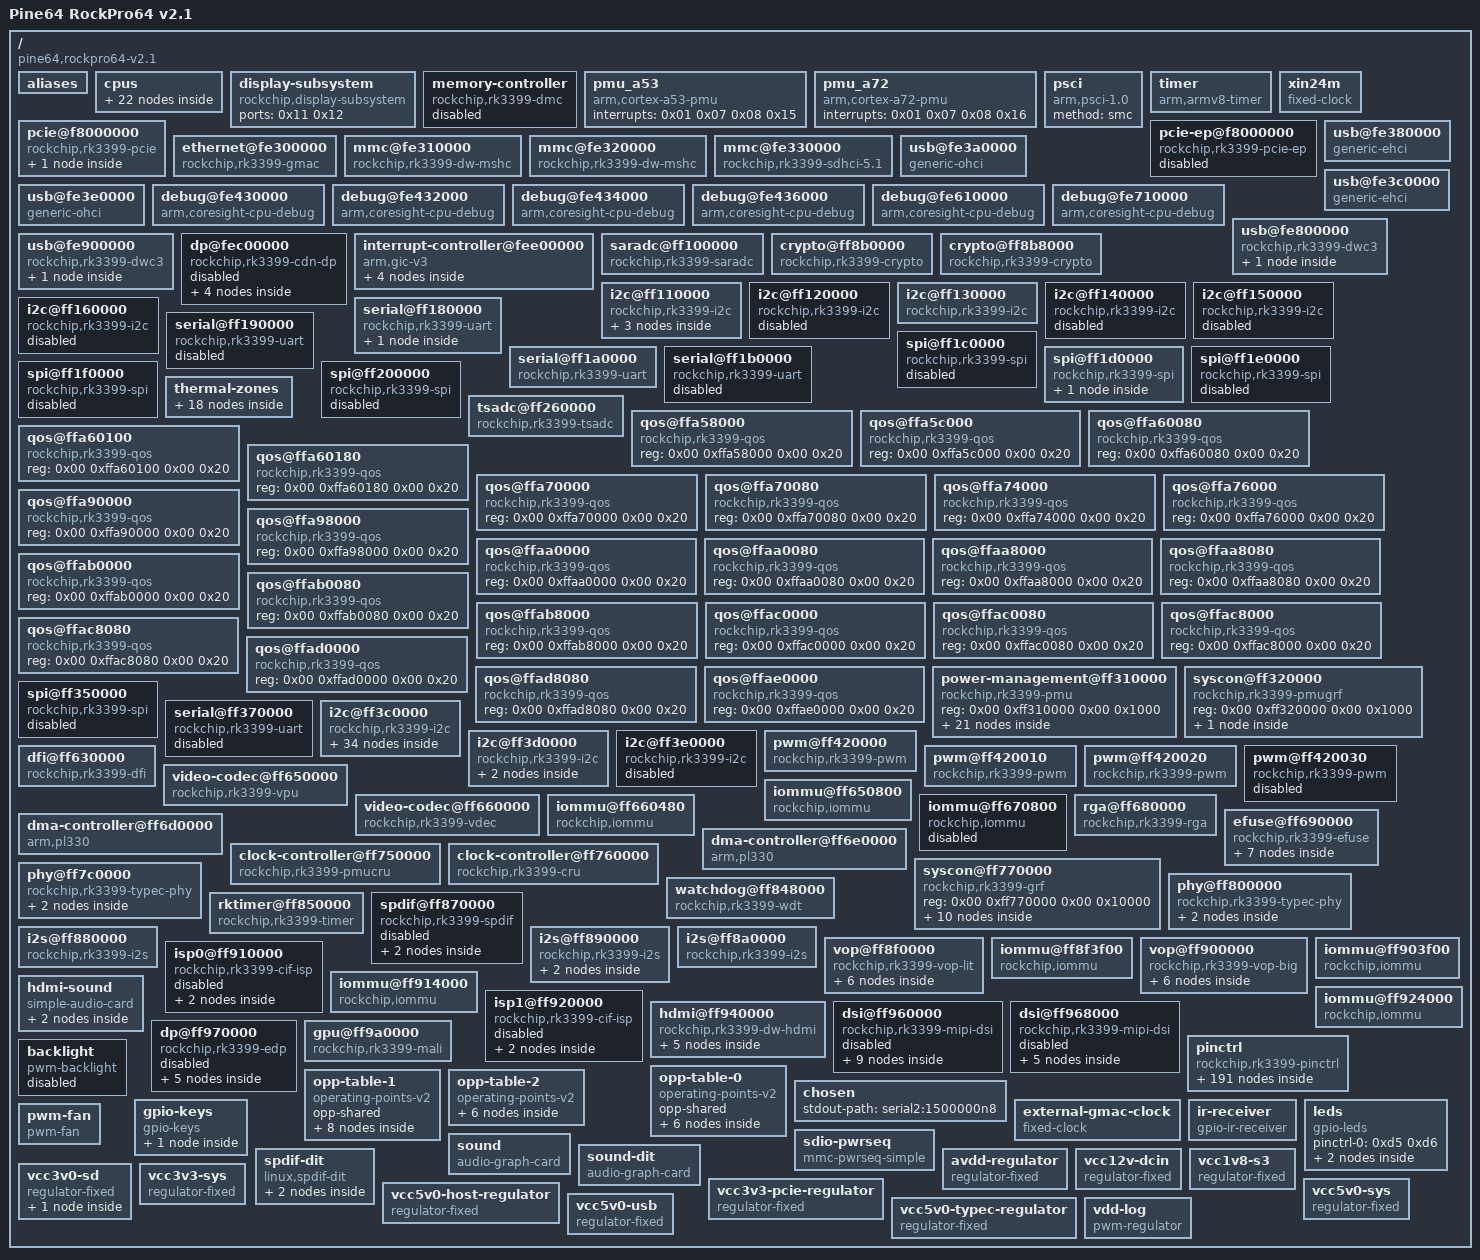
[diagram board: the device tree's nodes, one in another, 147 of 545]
/*
 * Copyright Linux Kernel Team
 *
 * SPDX-License-Identifier: GPL-2.0-only
 *
 * This file is derived from an intermediate build stage of the
 * Linux kernel. The licenses of all input files to this process
 * are compatible with GPL-2.0-only.
 */

/dts-v1/;

/ {
	compatible = "pine64,rockpro64-v2.1", "pine64,rockpro64", "rockchip,rk3399";
	interrupt-parent = <0x01>;
	#address-cells = <0x02>;
	#size-cells = <0x02>;
	model = "Pine64 RockPro64 v2.1";

	aliases {
		gpio0 = "/pinctrl/gpio@ff720000";
		gpio1 = "/pinctrl/gpio@ff730000";
		gpio2 = "/pinctrl/gpio@ff780000";
		gpio3 = "/pinctrl/gpio@ff788000";
		gpio4 = "/pinctrl/gpio@ff790000";
		i2c0 = "/i2c@ff3c0000";
		i2c1 = "/i2c@ff110000";
		i2c2 = "/i2c@ff120000";
		i2c3 = "/i2c@ff130000";
		i2c4 = "/i2c@ff3d0000";
		i2c5 = "/i2c@ff140000";
		i2c6 = "/i2c@ff150000";
		i2c7 = "/i2c@ff160000";
		i2c8 = "/i2c@ff3e0000";
		serial0 = "/serial@ff180000";
		serial1 = "/serial@ff190000";
		serial2 = "/serial@ff1a0000";
		serial3 = "/serial@ff1b0000";
		serial4 = "/serial@ff370000";
		spi0 = "/spi@ff1c0000";
		spi1 = "/spi@ff1d0000";
		spi2 = "/spi@ff1e0000";
		spi3 = "/spi@ff350000";
		spi4 = "/spi@ff1f0000";
		spi5 = "/spi@ff200000";
		ethernet0 = "/ethernet@fe300000";
		mmc0 = "/mmc@fe310000";
		mmc1 = "/mmc@fe320000";
		mmc2 = "/mmc@fe330000";
	};

	cpus {
		#address-cells = <0x02>;
		#size-cells = <0x00>;

		cpu-map {

			cluster0 {

				core0 {
					cpu = <0x02>;
				};

				core1 {
					cpu = <0x03>;
				};

				core2 {
					cpu = <0x04>;
				};

				core3 {
					cpu = <0x05>;
				};
			};

			cluster1 {

				core0 {
					cpu = <0x06>;
				};

				core1 {
					cpu = <0x07>;
				};
			};
		};

		cpu@0 {
			device_type = "cpu";
			compatible = "arm,cortex-a53";
			reg = <0x00 0x00>;
			enable-method = "psci";
			capacity-dmips-mhz = <0x1e5>;
			clocks = <0x08 0x08>;
			#cooling-cells = <0x02>;
			dynamic-power-coefficient = <0x64>;
			cpu-idle-states = <0x09 0x0a>;
			i-cache-size = <0x8000>;
			i-cache-line-size = <0x40>;
			i-cache-sets = <0x100>;
			d-cache-size = <0x8000>;
			d-cache-line-size = <0x40>;
			d-cache-sets = <0x80>;
			next-level-cache = <0x0b>;
			operating-points-v2 = <0x0c>;
			cpu-supply = <0x0d>;
			phandle = <0x02>;
		};

		cpu@1 {
			device_type = "cpu";
			compatible = "arm,cortex-a53";
			reg = <0x00 0x01>;
			enable-method = "psci";
			capacity-dmips-mhz = <0x1e5>;
			clocks = <0x08 0x08>;
			#cooling-cells = <0x02>;
			dynamic-power-coefficient = <0x64>;
			cpu-idle-states = <0x09 0x0a>;
			i-cache-size = <0x8000>;
			i-cache-line-size = <0x40>;
			i-cache-sets = <0x100>;
			d-cache-size = <0x8000>;
			d-cache-line-size = <0x40>;
			d-cache-sets = <0x80>;
			next-level-cache = <0x0b>;
			operating-points-v2 = <0x0c>;
			cpu-supply = <0x0d>;
			phandle = <0x03>;
		};

		cpu@2 {
			device_type = "cpu";
			compatible = "arm,cortex-a53";
			reg = <0x00 0x02>;
			enable-method = "psci";
			capacity-dmips-mhz = <0x1e5>;
			clocks = <0x08 0x08>;
			#cooling-cells = <0x02>;
			dynamic-power-coefficient = <0x64>;
			cpu-idle-states = <0x09 0x0a>;
			i-cache-size = <0x8000>;
			i-cache-line-size = <0x40>;
			i-cache-sets = <0x100>;
			d-cache-size = <0x8000>;
			d-cache-line-size = <0x40>;
			d-cache-sets = <0x80>;
			next-level-cache = <0x0b>;
			operating-points-v2 = <0x0c>;
			cpu-supply = <0x0d>;
			phandle = <0x04>;
		};

		cpu@3 {
			device_type = "cpu";
			compatible = "arm,cortex-a53";
			reg = <0x00 0x03>;
			enable-method = "psci";
			capacity-dmips-mhz = <0x1e5>;
			clocks = <0x08 0x08>;
			#cooling-cells = <0x02>;
			dynamic-power-coefficient = <0x64>;
			cpu-idle-states = <0x09 0x0a>;
			i-cache-size = <0x8000>;
			i-cache-line-size = <0x40>;
			i-cache-sets = <0x100>;
			d-cache-size = <0x8000>;
			d-cache-line-size = <0x40>;
			d-cache-sets = <0x80>;
			next-level-cache = <0x0b>;
			operating-points-v2 = <0x0c>;
			cpu-supply = <0x0d>;
			phandle = <0x05>;
		};

		cpu@100 {
			device_type = "cpu";
			compatible = "arm,cortex-a72";
			reg = <0x00 0x100>;
			enable-method = "psci";
			capacity-dmips-mhz = <0x400>;
			clocks = <0x08 0x09>;
			#cooling-cells = <0x02>;
			dynamic-power-coefficient = <0x1b4>;
			cpu-idle-states = <0x09 0x0a>;
			i-cache-size = <0xc000>;
			i-cache-line-size = <0x40>;
			i-cache-sets = <0x100>;
			d-cache-size = <0x8000>;
			d-cache-line-size = <0x40>;
			d-cache-sets = <0x100>;
			next-level-cache = <0x0e>;
			operating-points-v2 = <0x0f>;
			cpu-supply = <0x10>;
			phandle = <0x06>;

			thermal-idle {
				#cooling-cells = <0x02>;
				duration-us = <0x2710>;
				exit-latency-us = <0x1f4>;
			};
		};

		cpu@101 {
			device_type = "cpu";
			compatible = "arm,cortex-a72";
			reg = <0x00 0x101>;
			enable-method = "psci";
			capacity-dmips-mhz = <0x400>;
			clocks = <0x08 0x09>;
			#cooling-cells = <0x02>;
			dynamic-power-coefficient = <0x1b4>;
			cpu-idle-states = <0x09 0x0a>;
			i-cache-size = <0xc000>;
			i-cache-line-size = <0x40>;
			i-cache-sets = <0x100>;
			d-cache-size = <0x8000>;
			d-cache-line-size = <0x40>;
			d-cache-sets = <0x100>;
			next-level-cache = <0x0e>;
			operating-points-v2 = <0x0f>;
			cpu-supply = <0x10>;
			phandle = <0x07>;

			thermal-idle {
				#cooling-cells = <0x02>;
				duration-us = <0x2710>;
				exit-latency-us = <0x1f4>;
			};
		};

		l2-cache-cluster0 {
			compatible = "cache";
			cache-level = <0x02>;
			cache-unified;
			cache-size = <0x80000>;
			cache-line-size = <0x40>;
			cache-sets = <0x200>;
			phandle = <0x0b>;
		};

		l2-cache-cluster1 {
			compatible = "cache";
			cache-level = <0x02>;
			cache-unified;
			cache-size = <0x100000>;
			cache-line-size = <0x40>;
			cache-sets = <0x400>;
			phandle = <0x0e>;
		};

		idle-states {
			entry-method = "psci";

			cpu-sleep {
				compatible = "arm,idle-state";
				local-timer-stop;
				arm,psci-suspend-param = <0x10000>;
				entry-latency-us = <0x78>;
				exit-latency-us = <0xfa>;
				min-residency-us = <0x384>;
				phandle = <0x09>;
			};

			cluster-sleep {
				compatible = "arm,idle-state";
				local-timer-stop;
				arm,psci-suspend-param = <0x1010000>;
				entry-latency-us = <0x190>;
				exit-latency-us = <0x1f4>;
				min-residency-us = <0x7d0>;
				phandle = <0x0a>;
			};
		};
	};

	display-subsystem {
		compatible = "rockchip,display-subsystem";
		ports = <0x11 0x12>;
	};

	memory-controller {
		compatible = "rockchip,rk3399-dmc";
		rockchip,pmu = <0x13>;
		devfreq-events = <0x14>;
		clocks = <0x08 0xa8>;
		clock-names = "dmc_clk";
		status = "disabled";
	};

	pmu_a53 {
		compatible = "arm,cortex-a53-pmu";
		interrupts = <0x01 0x07 0x08 0x15>;
	};

	pmu_a72 {
		compatible = "arm,cortex-a72-pmu";
		interrupts = <0x01 0x07 0x08 0x16>;
	};

	psci {
		compatible = "arm,psci-1.0";
		method = "smc";
	};

	timer {
		compatible = "arm,armv8-timer";
		interrupts = <0x01 0x0d 0x08 0x00 0x01 0x0e 0x08 0x00 0x01 0x0b 0x08 0x00 0x01 0x0a 0x08 0x00>;
		arm,no-tick-in-suspend;
	};

	xin24m {
		compatible = "fixed-clock";
		clock-frequency = <0x16e3600>;
		clock-output-names = "xin24m";
		#clock-cells = <0x00>;
		phandle = <0x9f>;
	};

	pcie@f8000000 {
		compatible = "rockchip,rk3399-pcie";
		reg = <0x00 0xf8000000 0x00 0x2000000 0x00 0xfd000000 0x00 0x1000000>;
		reg-names = "axi-base", "apb-base";
		device_type = "pci";
		#address-cells = <0x03>;
		#size-cells = <0x02>;
		#interrupt-cells = <0x01>;
		aspm-no-l0s;
		bus-range = <0x00 0x1f>;
		clocks = <0x08 0xc5 0x08 0xc4 0x08 0x147 0x08 0xa0>;
		clock-names = "aclk", "aclk-perf", "hclk", "pm";
		interrupts = <0x00 0x31 0x04 0x00 0x00 0x32 0x04 0x00 0x00 0x33 0x04 0x00>;
		interrupt-names = "sys", "legacy", "client";
		interrupt-map-mask = <0x00 0x00 0x00 0x07>;
		interrupt-map = <0x00 0x00 0x00 0x01 0x17 0x00 0x00 0x00 0x00 0x02 0x17 0x01 0x00 0x00 0x00 0x03 0x17 0x02 0x00 0x00 0x00 0x04 0x17 0x03>;
		max-link-speed = <0x01>;
		msi-map = <0x00 0x18 0x00 0x1000>;
		phys = <0x19 0x00 0x19 0x01 0x19 0x02 0x19 0x03>;
		phy-names = "pcie-phy-0", "pcie-phy-1", "pcie-phy-2", "pcie-phy-3";
		ranges = <0x82000000 0x00 0xfa000000 0x00 0xfa000000 0x00 0x1e00000 0x81000000 0x00 0xfbe00000 0x00 0xfbe00000 0x00 0x100000>;
		resets = <0x08 0x82 0x08 0x83 0x08 0x84 0x08 0x85 0x08 0x86 0x08 0x81 0x08 0x80>;
		reset-names = "core", "mgmt", "mgmt-sticky", "pipe", "pm", "pclk", "aclk";
		status = "okay";
		ep-gpios = <0x1a 0x1c 0x00>;
		num-lanes = <0x04>;
		pinctrl-names = "default";
		pinctrl-0 = <0x1b>;
		vpcie12v-supply = <0x1c>;
		vpcie3v3-supply = <0x1d>;

		interrupt-controller {
			interrupt-controller;
			#address-cells = <0x00>;
			#interrupt-cells = <0x01>;
			phandle = <0x17>;
		};
	};

	pcie-ep@f8000000 {
		compatible = "rockchip,rk3399-pcie-ep";
		reg = <0x00 0xfd000000 0x00 0x1000000 0x00 0xfa000000 0x00 0x2000000>;
		reg-names = "apb-base", "mem-base";
		clocks = <0x08 0xc5 0x08 0xc4 0x08 0x147 0x08 0xa0>;
		clock-names = "aclk", "aclk-perf", "hclk", "pm";
		max-functions = [08];
		num-lanes = <0x04>;
		resets = <0x08 0x82 0x08 0x83 0x08 0x84 0x08 0x85 0x08 0x86 0x08 0x81 0x08 0x80>;
		reset-names = "core", "mgmt", "mgmt-sticky", "pipe", "pm", "pclk", "aclk";
		phys = <0x19 0x00 0x19 0x01 0x19 0x02 0x19 0x03>;
		phy-names = "pcie-phy-0", "pcie-phy-1", "pcie-phy-2", "pcie-phy-3";
		rockchip,max-outbound-regions = <0x20>;
		pinctrl-names = "default";
		pinctrl-0 = <0x1e>;
		status = "disabled";
	};

	ethernet@fe300000 {
		compatible = "rockchip,rk3399-gmac";
		reg = <0x00 0xfe300000 0x00 0x10000>;
		interrupts = <0x00 0x0c 0x04 0x00>;
		interrupt-names = "macirq";
		clocks = <0x08 0x69 0x08 0x67 0x08 0x68 0x08 0x66 0x08 0x6a 0x08 0xd5 0x08 0x166>;
		clock-names = "stmmaceth", "mac_clk_rx", "mac_clk_tx", "clk_mac_ref", "clk_mac_refout", "aclk_mac", "pclk_mac";
		power-domains = <0x1f 0x16>;
		resets = <0x08 0x89>;
		reset-names = "stmmaceth";
		rockchip,grf = <0x20>;
		snps,txpbl = <0x04>;
		status = "okay";
		assigned-clocks = <0x08 0xa6>;
		assigned-clock-parents = <0x21>;
		clock_in_out = "input";
		phy-supply = <0x22>;
		phy-mode = "rgmii";
		pinctrl-names = "default";
		pinctrl-0 = <0x23>;
		snps,reset-gpio = <0x24 0x0f 0x01>;
		snps,reset-active-low;
		snps,reset-delays-us = <0x00 0x2710 0xc350>;
		tx_delay = <0x28>;
		rx_delay = <0x11>;
	};

	mmc@fe310000 {
		compatible = "rockchip,rk3399-dw-mshc", "rockchip,rk3288-dw-mshc";
		reg = <0x00 0xfe310000 0x00 0x4000>;
		interrupts = <0x00 0x40 0x04 0x00>;
		max-frequency = <0x8f0d180>;
		clocks = <0x08 0x1ee 0x08 0x4d 0x08 0x9c 0x08 0x9d>;
		clock-names = "biu", "ciu", "ciu-drive", "ciu-sample";
		fifo-depth = <0x100>;
		power-domains = <0x1f 0x1c>;
		resets = <0x08 0x79>;
		reset-names = "reset";
		status = "okay";
		bus-width = <0x04>;
		cap-sd-highspeed;
		cap-sdio-irq;
		disable-wp;
		keep-power-in-suspend;
		mmc-pwrseq = <0x25>;
		non-removable;
		pinctrl-names = "default";
		pinctrl-0 = <0x26 0x27 0x28>;
		sd-uhs-sdr104;
	};

	mmc@fe320000 {
		compatible = "rockchip,rk3399-dw-mshc", "rockchip,rk3288-dw-mshc";
		reg = <0x00 0xfe320000 0x00 0x4000>;
		interrupts = <0x00 0x41 0x04 0x00>;
		max-frequency = <0x8f0d180>;
		assigned-clocks = <0x08 0x1cd>;
		assigned-clock-rates = <0xbebc200>;
		clocks = <0x08 0x1ce 0x08 0x4c 0x08 0x9a 0x08 0x9b>;
		clock-names = "biu", "ciu", "ciu-drive", "ciu-sample";
		fifo-depth = <0x100>;
		power-domains = <0x1f 0x1b>;
		resets = <0x08 0x7a>;
		reset-names = "reset";
		status = "okay";
		bus-width = <0x04>;
		cap-sd-highspeed;
		cd-gpios = <0x29 0x07 0x01>;
		disable-wp;
		pinctrl-names = "default";
		pinctrl-0 = <0x2a 0x2b 0x2c>;
		vmmc-supply = <0x2d>;
		vqmmc-supply = <0x2e>;
	};

	mmc@fe330000 {
		compatible = "rockchip,rk3399-sdhci-5.1", "arasan,sdhci-5.1";
		reg = <0x00 0xfe330000 0x00 0x10000>;
		interrupts = <0x00 0x0b 0x04 0x00>;
		arasan,soc-ctl-syscon = <0x20>;
		assigned-clocks = <0x08 0x4e>;
		assigned-clock-rates = <0xbebc200>;
		clocks = <0x08 0x4e 0x08 0xf0>;
		clock-names = "clk_xin", "clk_ahb";
		clock-output-names = "emmc_cardclock";
		#clock-cells = <0x00>;
		phys = <0x2f>;
		phy-names = "phy_arasan";
		power-domains = <0x1f 0x17>;
		disable-cqe-dcmd;
		status = "okay";
		bus-width = <0x08>;
		mmc-hs200-1_8v;
		non-removable;
		phandle = <0xa2>;
	};

	usb@fe380000 {
		compatible = "generic-ehci";
		reg = <0x00 0xfe380000 0x00 0x20000>;
		interrupts = <0x00 0x1a 0x04 0x00>;
		clocks = <0x08 0x1c8 0x08 0x1c9 0x30>;
		phys = <0x31>;
		phy-names = "usb";
		status = "okay";
	};

	usb@fe3a0000 {
		compatible = "generic-ohci";
		reg = <0x00 0xfe3a0000 0x00 0x20000>;
		interrupts = <0x00 0x1c 0x04 0x00>;
		clocks = <0x08 0x1c8 0x08 0x1c9 0x30>;
		phys = <0x31>;
		phy-names = "usb";
		status = "okay";
	};

	usb@fe3c0000 {
		compatible = "generic-ehci";
		reg = <0x00 0xfe3c0000 0x00 0x20000>;
		interrupts = <0x00 0x1e 0x04 0x00>;
		clocks = <0x08 0x1ca 0x08 0x1cb 0x32>;
		phys = <0x33>;
		phy-names = "usb";
		status = "okay";
	};

	usb@fe3e0000 {
		compatible = "generic-ohci";
		reg = <0x00 0xfe3e0000 0x00 0x20000>;
		interrupts = <0x00 0x20 0x04 0x00>;
		clocks = <0x08 0x1ca 0x08 0x1cb 0x32>;
		phys = <0x33>;
		phy-names = "usb";
		status = "okay";
	};

	debug@fe430000 {
		compatible = "arm,coresight-cpu-debug", "arm,primecell";
		reg = <0x00 0xfe430000 0x00 0x1000>;
		clocks = <0x08 0x14d>;
		clock-names = "apb_pclk";
		cpu = <0x02>;
	};

	debug@fe432000 {
		compatible = "arm,coresight-cpu-debug", "arm,primecell";
		reg = <0x00 0xfe432000 0x00 0x1000>;
		clocks = <0x08 0x14d>;
		clock-names = "apb_pclk";
		cpu = <0x03>;
	};

	debug@fe434000 {
		compatible = "arm,coresight-cpu-debug", "arm,primecell";
		reg = <0x00 0xfe434000 0x00 0x1000>;
		clocks = <0x08 0x14d>;
		clock-names = "apb_pclk";
		cpu = <0x04>;
	};

	debug@fe436000 {
		compatible = "arm,coresight-cpu-debug", "arm,primecell";
		reg = <0x00 0xfe436000 0x00 0x1000>;
		clocks = <0x08 0x14d>;
		clock-names = "apb_pclk";
		cpu = <0x05>;
	};

	debug@fe610000 {
		compatible = "arm,coresight-cpu-debug", "arm,primecell";
		reg = <0x00 0xfe610000 0x00 0x1000>;
		clocks = <0x08 0x14c>;
		clock-names = "apb_pclk";
		cpu = <0x06>;
	};

	debug@fe710000 {
		compatible = "arm,coresight-cpu-debug", "arm,primecell";
		reg = <0x00 0xfe710000 0x00 0x1000>;
		clocks = <0x08 0x14c>;
		clock-names = "apb_pclk";
		cpu = <0x07>;
	};

	usb@fe800000 {
		compatible = "rockchip,rk3399-dwc3";
		#address-cells = <0x02>;
		#size-cells = <0x02>;
		ranges;
		clocks = <0x08 0x81 0x08 0x83 0x08 0xf6 0x08 0xf8 0x08 0xf4 0x08 0xf9>;
		clock-names = "ref_clk", "suspend_clk", "bus_clk", "aclk_usb3_rksoc_axi_perf", "aclk_usb3", "grf_clk";
		resets = <0x08 0x125>;
		reset-names = "usb3-otg";
		status = "okay";

		usb@fe800000 {
			compatible = "snps,dwc3";
			reg = <0x00 0xfe800000 0x00 0x100000>;
			interrupts = <0x00 0x69 0x04 0x00>;
			clocks = <0x08 0x81 0x08 0xf6 0x08 0x83>;
			clock-names = "ref", "bus_early", "suspend";
			dr_mode = "host";
			phys = <0x34 0x35>;
			phy-names = "usb2-phy", "usb3-phy";
			phy_type = "utmi_wide";
			snps,dis_enblslpm_quirk;
			snps,dis-u2-freeclk-exists-quirk;
			snps,dis_u2_susphy_quirk;
			snps,dis-del-phy-power-chg-quirk;
			snps,dis-tx-ipgap-linecheck-quirk;
			power-domains = <0x1f 0x18>;
			status = "okay";
		};
	};

	usb@fe900000 {
		compatible = "rockchip,rk3399-dwc3";
		#address-cells = <0x02>;
		#size-cells = <0x02>;
		ranges;
		clocks = <0x08 0x82 0x08 0x84 0x08 0xf7 0x08 0xf8 0x08 0xf4 0x08 0xf9>;
		clock-names = "ref_clk", "suspend_clk", "bus_clk", "aclk_usb3_rksoc_axi_perf", "aclk_usb3", "grf_clk";
		resets = <0x08 0x126>;
		reset-names = "usb3-otg";
		status = "okay";

		usb@fe900000 {
			compatible = "snps,dwc3";
			reg = <0x00 0xfe900000 0x00 0x100000>;
			interrupts = <0x00 0x6e 0x04 0x00>;
			clocks = <0x08 0x82 0x08 0xf7 0x08 0x84>;
			clock-names = "ref", "bus_early", "suspend";
			dr_mode = "host";
			phys = <0x36 0x37>;
			phy-names = "usb2-phy", "usb3-phy";
			phy_type = "utmi_wide";
			snps,dis_enblslpm_quirk;
			snps,dis-u2-freeclk-exists-quirk;
			snps,dis_u2_susphy_quirk;
			snps,dis-del-phy-power-chg-quirk;
			snps,dis-tx-ipgap-linecheck-quirk;
			power-domains = <0x1f 0x18>;
			status = "okay";
		};
	};

	dp@fec00000 {
		compatible = "rockchip,rk3399-cdn-dp";
		reg = <0x00 0xfec00000 0x00 0x100000>;
		interrupts = <0x00 0x09 0x04 0x00>;
		assigned-clocks = <0x08 0x72 0x08 0xa1>;
		assigned-clock-rates = <0x5f5e100 0xbebc200>;
		clocks = <0x08 0x72 0x08 0x175 0x08 0xa1 0x08 0x16f>;
		clock-names = "core-clk", "pclk", "spdif", "grf";
		phys = <0x38 0x39>;
		power-domains = <0x1f 0x15>;
		resets = <0x08 0x103 0x08 0x148 0x08 0x14a 0x08 0xfd>;
		reset-names = "spdif", "dptx", "apb", "core";
		rockchip,grf = <0x20>;
		#sound-dai-cells = <0x01>;
		status = "disabled";

		ports {

			port {
				#address-cells = <0x01>;
				#size-cells = <0x00>;

				endpoint@0 {
					reg = <0x00>;
					remote-endpoint = <0x3a>;
					phandle = <0xb4>;
				};

				endpoint@1 {
					reg = <0x01>;
					remote-endpoint = <0x3b>;
					phandle = <0xae>;
				};
			};
		};
	};

	interrupt-controller@fee00000 {
		compatible = "arm,gic-v3";
		#interrupt-cells = <0x04>;
		#address-cells = <0x02>;
		#size-cells = <0x02>;
		ranges;
		interrupt-controller;
		reg = <0x00 0xfee00000 0x00 0x10000 0x00 0xfef00000 0x00 0xc0000 0x00 0xfff00000 0x00 0x10000 0x00 0xfff10000 0x00 0x10000 0x00 0xfff20000 0x00 0x10000>;
		interrupts = <0x01 0x09 0x04 0x00>;
		phandle = <0x01>;

		msi-controller@fee20000 {
			compatible = "arm,gic-v3-its";
			msi-controller;
			#msi-cells = <0x01>;
			reg = <0x00 0xfee20000 0x00 0x20000>;
			phandle = <0x18>;
		};

		ppi-partitions {

			interrupt-partition-0 {
				affinity = <0x02 0x03 0x04 0x05>;
				phandle = <0x15>;
			};

			interrupt-partition-1 {
				affinity = <0x06 0x07>;
				phandle = <0x16>;
			};
		};
	};

	saradc@ff100000 {
		compatible = "rockchip,rk3399-saradc";
		reg = <0x00 0xff100000 0x00 0x100>;
		interrupts = <0x00 0x3e 0x04 0x00>;
		#io-channel-cells = <0x01>;
		clocks = <0x08 0x50 0x08 0x165>;
		clock-names = "saradc", "apb_pclk";
		resets = <0x08 0xd4>;
		reset-names = "saradc-apb";
		status = "okay";
		vref-supply = <0x3c>;
	};

	crypto@ff8b0000 {
		compatible = "rockchip,rk3399-crypto";
		reg = <0x00 0xff8b0000 0x00 0x4000>;
		interrupts = <0x00 0x00 0x04 0x00>;
		clocks = <0x08 0x1d0 0x08 0x1d2 0x08 0x85>;
		clock-names = "hclk_master", "hclk_slave", "sclk";
		resets = <0x08 0xb5 0x08 0xae 0x08 0xaf>;
		reset-names = "master", "slave", "crypto-rst";
	};

	crypto@ff8b8000 {
		compatible = "rockchip,rk3399-crypto";
		reg = <0x00 0xff8b8000 0x00 0x4000>;
		interrupts = <0x00 0x87 0x04 0x00>;
		clocks = <0x08 0x1d1 0x08 0x1d3 0x08 0x86>;
		clock-names = "hclk_master", "hclk_slave", "sclk";
		resets = <0x08 0xba 0x08 0xb8 0x08 0xb9>;
		reset-names = "master", "slave", "crypto-rst";
	};

	i2c@ff110000 {
		compatible = "rockchip,rk3399-i2c";
		reg = <0x00 0xff110000 0x00 0x1000>;
		assigned-clocks = <0x08 0x41>;
		assigned-clock-rates = <0xbebc200>;
		clocks = <0x08 0x41 0x08 0x155>;
		clock-names = "i2c", "pclk";
		interrupts = <0x00 0x3b 0x04 0x00>;
		pinctrl-names = "default";
		pinctrl-0 = <0x3d>;
		#address-cells = <0x01>;
		#size-cells = <0x00>;
		status = "okay";
		i2c-scl-rising-time-ns = <0x12c>;
		i2c-scl-falling-time-ns = <0x0f>;

		codec@11 {
			compatible = "everest,es8316";
			reg = <0x11>;
			clocks = <0x08 0x59>;
			clock-names = "mclk";
			#sound-dai-cells = <0x00>;

			port {

				endpoint {
					remote-endpoint = <0x3e>;
					phandle = <0xa8>;
				};
			};
		};
	};

	i2c@ff120000 {
		compatible = "rockchip,rk3399-i2c";
		reg = <0x00 0xff120000 0x00 0x1000>;
		assigned-clocks = <0x08 0x42>;
		assigned-clock-rates = <0xbebc200>;
		clocks = <0x08 0x42 0x08 0x156>;
		clock-names = "i2c", "pclk";
		interrupts = <0x00 0x23 0x04 0x00>;
		pinctrl-names = "default";
		pinctrl-0 = <0x3f>;
		#address-cells = <0x01>;
		#size-cells = <0x00>;
		status = "disabled";
	};

	i2c@ff130000 {
		compatible = "rockchip,rk3399-i2c";
		reg = <0x00 0xff130000 0x00 0x1000>;
		assigned-clocks = <0x08 0x43>;
		assigned-clock-rates = <0xbebc200>;
		clocks = <0x08 0x43 0x08 0x157>;
		clock-names = "i2c", "pclk";
		interrupts = <0x00 0x22 0x04 0x00>;
		pinctrl-names = "default";
		pinctrl-0 = <0x40>;
		#address-cells = <0x01>;
		#size-cells = <0x00>;
		status = "okay";
		i2c-scl-rising-time-ns = <0x1c2>;
		i2c-scl-falling-time-ns = <0x0f>;
		phandle = <0xbb>;
	};

	i2c@ff140000 {
		compatible = "rockchip,rk3399-i2c";
		reg = <0x00 0xff140000 0x00 0x1000>;
		assigned-clocks = <0x08 0x44>;
		assigned-clock-rates = <0xbebc200>;
		clocks = <0x08 0x44 0x08 0x158>;
		clock-names = "i2c", "pclk";
		interrupts = <0x00 0x26 0x04 0x00>;
		pinctrl-names = "default";
		pinctrl-0 = <0x41>;
		#address-cells = <0x01>;
		#size-cells = <0x00>;
		status = "disabled";
	};

	i2c@ff150000 {
		compatible = "rockchip,rk3399-i2c";
		reg = <0x00 0xff150000 0x00 0x1000>;
		assigned-clocks = <0x08 0x45>;
		assigned-clock-rates = <0xbebc200>;
		clocks = <0x08 0x45 0x08 0x159>;
		clock-names = "i2c", "pclk";
		interrupts = <0x00 0x25 0x04 0x00>;
		pinctrl-names = "default";
		pinctrl-0 = <0x42>;
		#address-cells = <0x01>;
		#size-cells = <0x00>;
		status = "disabled";
	};

	i2c@ff160000 {
		compatible = "rockchip,rk3399-i2c";
		reg = <0x00 0xff160000 0x00 0x1000>;
		assigned-clocks = <0x08 0x46>;
		assigned-clock-rates = <0xbebc200>;
		clocks = <0x08 0x46 0x08 0x15a>;
		clock-names = "i2c", "pclk";
		interrupts = <0x00 0x24 0x04 0x00>;
		pinctrl-names = "default";
		pinctrl-0 = <0x43>;
		#address-cells = <0x01>;
		#size-cells = <0x00>;
		status = "disabled";
	};

	serial@ff180000 {
		compatible = "rockchip,rk3399-uart", "snps,dw-apb-uart";
		reg = <0x00 0xff180000 0x00 0x100>;
		clocks = <0x08 0x51 0x08 0x160>;
		clock-names = "baudclk", "apb_pclk";
		interrupts = <0x00 0x63 0x04 0x00>;
		reg-shift = <0x02>;
		reg-io-width = <0x04>;
		pinctrl-names = "default";
		pinctrl-0 = <0x44 0x45 0x46>;
		status = "okay";

		bluetooth {
			compatible = "brcm,bcm43438-bt";
			clocks = <0x47 0x01>;
			clock-names = "lpo";
			device-wakeup-gpios = <0x1a 0x1b 0x00>;
			host-wakeup-gpios = <0x29 0x04 0x00>;
			shutdown-gpios = <0x29 0x09 0x00>;
			pinctrl-names = "default";
			pinctrl-0 = <0x48 0x49 0x4a>;
			vbat-supply = <0x4b>;
			vddio-supply = <0x4c>;
		};
	};

	serial@ff190000 {
		compatible = "rockchip,rk3399-uart", "snps,dw-apb-uart";
		reg = <0x00 0xff190000 0x00 0x100>;
		clocks = <0x08 0x52 0x08 0x161>;
		clock-names = "baudclk", "apb_pclk";
		interrupts = <0x00 0x62 0x04 0x00>;
		reg-shift = <0x02>;
		reg-io-width = <0x04>;
		pinctrl-names = "default";
		pinctrl-0 = <0x4d>;
		status = "disabled";
	};

	serial@ff1a0000 {
		compatible = "rockchip,rk3399-uart", "snps,dw-apb-uart";
		reg = <0x00 0xff1a0000 0x00 0x100>;
		clocks = <0x08 0x53 0x08 0x162>;
		clock-names = "baudclk", "apb_pclk";
		interrupts = <0x00 0x64 0x04 0x00>;
		reg-shift = <0x02>;
		reg-io-width = <0x04>;
		pinctrl-names = "default";
		pinctrl-0 = <0x4e>;
		status = "okay";
	};

	serial@ff1b0000 {
		compatible = "rockchip,rk3399-uart", "snps,dw-apb-uart";
		reg = <0x00 0xff1b0000 0x00 0x100>;
		clocks = <0x08 0x54 0x08 0x163>;
		clock-names = "baudclk", "apb_pclk";
		interrupts = <0x00 0x65 0x04 0x00>;
		reg-shift = <0x02>;
		reg-io-width = <0x04>;
		pinctrl-names = "default";
		pinctrl-0 = <0x4f>;
		status = "disabled";
	};

	spi@ff1c0000 {
		compatible = "rockchip,rk3399-spi", "rockchip,rk3066-spi";
		reg = <0x00 0xff1c0000 0x00 0x1000>;
		clocks = <0x08 0x47 0x08 0x15b>;
		clock-names = "spiclk", "apb_pclk";
		interrupts = <0x00 0x44 0x04 0x00>;
		dmas = <0x50 0x0a 0x50 0x0b>;
		dma-names = "tx", "rx";
		pinctrl-names = "default";
		pinctrl-0 = <0x51 0x52 0x53 0x54>;
		#address-cells = <0x01>;
		#size-cells = <0x00>;
		status = "disabled";
	};

	spi@ff1d0000 {
		compatible = "rockchip,rk3399-spi", "rockchip,rk3066-spi";
		reg = <0x00 0xff1d0000 0x00 0x1000>;
		clocks = <0x08 0x48 0x08 0x15c>;
		clock-names = "spiclk", "apb_pclk";
		interrupts = <0x00 0x35 0x04 0x00>;
		dmas = <0x50 0x0c 0x50 0x0d>;
		dma-names = "tx", "rx";
		pinctrl-names = "default";
		pinctrl-0 = <0x55 0x56 0x57 0x58>;
		#address-cells = <0x01>;
		#size-cells = <0x00>;
		status = "okay";

		flash@0 {
			compatible = "jedec,spi-nor";
			reg = <0x00>;
			spi-max-frequency = <0x989680>;
		};
	};

	spi@ff1e0000 {
		compatible = "rockchip,rk3399-spi", "rockchip,rk3066-spi";
		reg = <0x00 0xff1e0000 0x00 0x1000>;
		clocks = <0x08 0x49 0x08 0x15d>;
		clock-names = "spiclk", "apb_pclk";
		interrupts = <0x00 0x34 0x04 0x00>;
		dmas = <0x50 0x0e 0x50 0x0f>;
		dma-names = "tx", "rx";
		pinctrl-names = "default";
		pinctrl-0 = <0x59 0x5a 0x5b 0x5c>;
		#address-cells = <0x01>;
		#size-cells = <0x00>;
		status = "disabled";
	};

	spi@ff1f0000 {
		compatible = "rockchip,rk3399-spi", "rockchip,rk3066-spi";
		reg = <0x00 0xff1f0000 0x00 0x1000>;
		clocks = <0x08 0x4a 0x08 0x15e>;
		clock-names = "spiclk", "apb_pclk";
		interrupts = <0x00 0x43 0x04 0x00>;
		dmas = <0x50 0x12 0x50 0x13>;
		dma-names = "tx", "rx";
		pinctrl-names = "default";
		pinctrl-0 = <0x5d 0x5e 0x5f 0x60>;
		#address-cells = <0x01>;
		#size-cells = <0x00>;
		status = "disabled";
	};

	spi@ff200000 {
		compatible = "rockchip,rk3399-spi", "rockchip,rk3066-spi";
		reg = <0x00 0xff200000 0x00 0x1000>;
		clocks = <0x08 0x4b 0x08 0x15f>;
		clock-names = "spiclk", "apb_pclk";
		interrupts = <0x00 0x84 0x04 0x00>;
		dmas = <0x61 0x08 0x61 0x09>;
		dma-names = "tx", "rx";
		pinctrl-names = "default";
		pinctrl-0 = <0x62 0x63 0x64 0x65>;
		power-domains = <0x1f 0x1c>;
		#address-cells = <0x01>;
		#size-cells = <0x00>;
		status = "disabled";
	};

	thermal-zones {

		cpu-thermal {
			polling-delay-passive = <0x64>;
			polling-delay = <0x3e8>;
			thermal-sensors = <0x66 0x00>;

			trips {

				cpu_alert0 {
					temperature = <0x11170>;
					hysteresis = <0x7d0>;
					type = "passive";
					phandle = <0x67>;
				};

				cpu_alert1 {
					temperature = <0x124f8>;
					hysteresis = <0x7d0>;
					type = "passive";
					phandle = <0x68>;
				};

				cpu_crit {
					temperature = <0x17318>;
					hysteresis = <0x7d0>;
					type = "critical";
				};

				cpu_warm {
					temperature = <0xd6d8>;
					hysteresis = <0x7d0>;
					type = "active";
					phandle = <0x69>;
				};

				cpu_hot {
					temperature = <0xfde8>;
					hysteresis = <0x7d0>;
					type = "active";
					phandle = <0x6b>;
				};
			};

			cooling-maps {

				map0 {
					trip = <0x67>;
					cooling-device = <0x06 0xffffffff 0xffffffff 0x07 0xffffffff 0xffffffff>;
				};

				map1 {
					trip = <0x68>;
					cooling-device = <0x02 0xffffffff 0xffffffff 0x03 0xffffffff 0xffffffff 0x04 0xffffffff 0xffffffff 0x05 0xffffffff 0xffffffff 0x06 0xffffffff 0xffffffff 0x07 0xffffffff 0xffffffff>;
				};

				map2 {
					trip = <0x69>;
					cooling-device = <0x6a 0xffffffff 0x01>;
				};

				map3 {
					trip = <0x6b>;
					cooling-device = <0x6a 0x02 0xffffffff>;
				};
			};
		};

		gpu-thermal {
			polling-delay-passive = <0x64>;
			polling-delay = <0x3e8>;
			thermal-sensors = <0x66 0x01>;

			trips {

				gpu_alert0 {
					temperature = <0x124f8>;
					hysteresis = <0x7d0>;
					type = "passive";
					phandle = <0x6c>;
				};

				gpu_crit {
					temperature = <0x17318>;
					hysteresis = <0x7d0>;
					type = "critical";
				};
			};

			cooling-maps {

				map0 {
					trip = <0x6c>;
					cooling-device = <0x6d 0xffffffff 0xffffffff>;
				};
			};
		};
	};

	tsadc@ff260000 {
		compatible = "rockchip,rk3399-tsadc";
		reg = <0x00 0xff260000 0x00 0x100>;
		interrupts = <0x00 0x61 0x04 0x00>;
		assigned-clocks = <0x08 0x4f>;
		assigned-clock-rates = <0xb71b0>;
		clocks = <0x08 0x4f 0x08 0x164>;
		clock-names = "tsadc", "apb_pclk";
		resets = <0x08 0xe8>;
		reset-names = "tsadc-apb";
		rockchip,grf = <0x20>;
		rockchip,hw-tshut-temp = <0x17318>;
		pinctrl-names = "init", "default", "sleep";
		pinctrl-0 = <0x6e>;
		pinctrl-1 = <0x6f>;
		pinctrl-2 = <0x6e>;
		#thermal-sensor-cells = <0x01>;
		status = "okay";
		rockchip,hw-tshut-mode = <0x01>;
		rockchip,hw-tshut-polarity = <0x01>;
		phandle = <0x66>;
	};

	qos@ffa58000 {
		compatible = "rockchip,rk3399-qos", "syscon";
		reg = <0x00 0xffa58000 0x00 0x20>;
		phandle = <0x77>;
	};

	qos@ffa5c000 {
		compatible = "rockchip,rk3399-qos", "syscon";
		reg = <0x00 0xffa5c000 0x00 0x20>;
		phandle = <0x78>;
	};

	qos@ffa60080 {
		compatible = "rockchip,rk3399-qos", "syscon";
		reg = <0x00 0xffa60080 0x00 0x20>;
	};

	qos@ffa60100 {
		compatible = "rockchip,rk3399-qos", "syscon";
		reg = <0x00 0xffa60100 0x00 0x20>;
	};

	qos@ffa60180 {
		compatible = "rockchip,rk3399-qos", "syscon";
		reg = <0x00 0xffa60180 0x00 0x20>;
	};

	qos@ffa70000 {
		compatible = "rockchip,rk3399-qos", "syscon";
		reg = <0x00 0xffa70000 0x00 0x20>;
		phandle = <0x7b>;
	};

	qos@ffa70080 {
		compatible = "rockchip,rk3399-qos", "syscon";
		reg = <0x00 0xffa70080 0x00 0x20>;
		phandle = <0x7c>;
	};

	qos@ffa74000 {
		compatible = "rockchip,rk3399-qos", "syscon";
		reg = <0x00 0xffa74000 0x00 0x20>;
		phandle = <0x79>;
	};

	qos@ffa76000 {
		compatible = "rockchip,rk3399-qos", "syscon";
		reg = <0x00 0xffa76000 0x00 0x20>;
		phandle = <0x7a>;
	};

	qos@ffa90000 {
		compatible = "rockchip,rk3399-qos", "syscon";
		reg = <0x00 0xffa90000 0x00 0x20>;
		phandle = <0x7d>;
	};

	qos@ffa98000 {
		compatible = "rockchip,rk3399-qos", "syscon";
		reg = <0x00 0xffa98000 0x00 0x20>;
		phandle = <0x70>;
	};

	qos@ffaa0000 {
		compatible = "rockchip,rk3399-qos", "syscon";
		reg = <0x00 0xffaa0000 0x00 0x20>;
		phandle = <0x7e>;
	};

	qos@ffaa0080 {
		compatible = "rockchip,rk3399-qos", "syscon";
		reg = <0x00 0xffaa0080 0x00 0x20>;
		phandle = <0x7f>;
	};

	qos@ffaa8000 {
		compatible = "rockchip,rk3399-qos", "syscon";
		reg = <0x00 0xffaa8000 0x00 0x20>;
		phandle = <0x80>;
	};

	qos@ffaa8080 {
		compatible = "rockchip,rk3399-qos", "syscon";
		reg = <0x00 0xffaa8080 0x00 0x20>;
		phandle = <0x81>;
	};

	qos@ffab0000 {
		compatible = "rockchip,rk3399-qos", "syscon";
		reg = <0x00 0xffab0000 0x00 0x20>;
		phandle = <0x71>;
	};

	qos@ffab0080 {
		compatible = "rockchip,rk3399-qos", "syscon";
		reg = <0x00 0xffab0080 0x00 0x20>;
		phandle = <0x72>;
	};

	qos@ffab8000 {
		compatible = "rockchip,rk3399-qos", "syscon";
		reg = <0x00 0xffab8000 0x00 0x20>;
		phandle = <0x73>;
	};

	qos@ffac0000 {
		compatible = "rockchip,rk3399-qos", "syscon";
		reg = <0x00 0xffac0000 0x00 0x20>;
		phandle = <0x74>;
	};

	qos@ffac0080 {
		compatible = "rockchip,rk3399-qos", "syscon";
		reg = <0x00 0xffac0080 0x00 0x20>;
		phandle = <0x75>;
	};

	qos@ffac8000 {
		compatible = "rockchip,rk3399-qos", "syscon";
		reg = <0x00 0xffac8000 0x00 0x20>;
		phandle = <0x82>;
	};

	qos@ffac8080 {
		compatible = "rockchip,rk3399-qos", "syscon";
		reg = <0x00 0xffac8080 0x00 0x20>;
		phandle = <0x83>;
	};

	qos@ffad0000 {
		compatible = "rockchip,rk3399-qos", "syscon";
		reg = <0x00 0xffad0000 0x00 0x20>;
		phandle = <0x84>;
	};

	qos@ffad8080 {
		compatible = "rockchip,rk3399-qos", "syscon";
		reg = <0x00 0xffad8080 0x00 0x20>;
	};

	qos@ffae0000 {
		compatible = "rockchip,rk3399-qos", "syscon";
		reg = <0x00 0xffae0000 0x00 0x20>;
		phandle = <0x76>;
	};

	power-management@ff310000 {
		compatible = "rockchip,rk3399-pmu", "syscon", "simple-mfd";
		reg = <0x00 0xff310000 0x00 0x1000>;

		power-controller {
			compatible = "rockchip,rk3399-power-controller";
			#power-domain-cells = <0x01>;
			#address-cells = <0x01>;
			#size-cells = <0x00>;
			phandle = <0x1f>;

			power-domain@34 {
				reg = <0x22>;
				clocks = <0x08 0xe1 0x08 0x1dd>;
				pm_qos = <0x70>;
				#power-domain-cells = <0x00>;
			};

			power-domain@33 {
				reg = <0x21>;
				clocks = <0x08 0xdc 0x08 0x1e5>;
				pm_qos = <0x71 0x72>;
				#power-domain-cells = <0x00>;
			};

			power-domain@31 {
				reg = <0x1f>;
				clocks = <0x08 0xeb 0x08 0x1ea>;
				pm_qos = <0x73>;
				#power-domain-cells = <0x00>;
			};

			power-domain@32 {
				reg = <0x20>;
				clocks = <0x08 0xed 0x08 0x1ec 0x08 0x9f 0x08 0x9e>;
				pm_qos = <0x74 0x75>;
				#power-domain-cells = <0x00>;
			};

			power-domain@35 {
				reg = <0x23>;
				clocks = <0x08 0xd0>;
				pm_qos = <0x76>;
				#power-domain-cells = <0x00>;
			};

			power-domain@25 {
				reg = <0x19>;
				clocks = <0x08 0x16c>;
				#power-domain-cells = <0x00>;
			};

			power-domain@23 {
				reg = <0x17>;
				clocks = <0x08 0xf0>;
				pm_qos = <0x77>;
				#power-domain-cells = <0x00>;
			};

			power-domain@22 {
				reg = <0x16>;
				clocks = <0x08 0xd5 0x08 0x166>;
				pm_qos = <0x78>;
				#power-domain-cells = <0x00>;
			};

			power-domain@27 {
				reg = <0x1b>;
				clocks = <0x08 0x1ce 0x08 0x4c>;
				pm_qos = <0x79>;
				#power-domain-cells = <0x00>;
			};

			power-domain@28 {
				reg = <0x1c>;
				clocks = <0x08 0x1ee>;
				pm_qos = <0x7a>;
				#power-domain-cells = <0x00>;
			};

			power-domain@8 {
				reg = <0x08>;
				clocks = <0x08 0x7e 0x08 0x7d>;
				#power-domain-cells = <0x00>;
			};

			power-domain@9 {
				reg = <0x09>;
				clocks = <0x08 0x80 0x08 0x7f>;
				#power-domain-cells = <0x00>;
			};

			power-domain@24 {
				reg = <0x18>;
				clocks = <0x08 0xf4>;
				pm_qos = <0x7b 0x7c>;
				#power-domain-cells = <0x00>;
			};

			power-domain@15 {
				reg = <0x0f>;
				#power-domain-cells = <0x01>;
				#address-cells = <0x01>;
				#size-cells = <0x00>;

				power-domain@21 {
					reg = <0x15>;
					clocks = <0x08 0xde 0x08 0x1e7 0x08 0x172>;
					pm_qos = <0x7d>;
					#power-domain-cells = <0x00>;
				};

				power-domain@19 {
					reg = <0x13>;
					clocks = <0x08 0xe5 0x08 0x1df>;
					pm_qos = <0x7e 0x7f>;
					#power-domain-cells = <0x00>;
				};

				power-domain@20 {
					reg = <0x14>;
					clocks = <0x08 0xe6 0x08 0x1e0>;
					pm_qos = <0x80 0x81>;
					#power-domain-cells = <0x00>;
				};

				power-domain@16 {
					reg = <0x10>;
					#power-domain-cells = <0x01>;
					#address-cells = <0x01>;
					#size-cells = <0x00>;

					power-domain@17 {
						reg = <0x11>;
						clocks = <0x08 0xd9 0x08 0x1d9>;
						pm_qos = <0x82 0x83>;
						#power-domain-cells = <0x00>;
					};

					power-domain@18 {
						reg = <0x12>;
						clocks = <0x08 0xdb 0x08 0x1db>;
						pm_qos = <0x84>;
						#power-domain-cells = <0x00>;
					};
				};
			};
		};
	};

	syscon@ff320000 {
		compatible = "rockchip,rk3399-pmugrf", "syscon", "simple-mfd";
		reg = <0x00 0xff320000 0x00 0x1000>;
		phandle = <0x13>;

		io-domains {
			compatible = "rockchip,rk3399-pmu-io-voltage-domain";
			status = "okay";
			pmu1830-supply = <0x85>;
		};
	};

	spi@ff350000 {
		compatible = "rockchip,rk3399-spi", "rockchip,rk3066-spi";
		reg = <0x00 0xff350000 0x00 0x1000>;
		clocks = <0x86 0x03 0x86 0x1f>;
		clock-names = "spiclk", "apb_pclk";
		interrupts = <0x00 0x3c 0x04 0x00>;
		pinctrl-names = "default";
		pinctrl-0 = <0x87 0x88 0x89 0x8a>;
		#address-cells = <0x01>;
		#size-cells = <0x00>;
		status = "disabled";
	};

	serial@ff370000 {
		compatible = "rockchip,rk3399-uart", "snps,dw-apb-uart";
		reg = <0x00 0xff370000 0x00 0x100>;
		clocks = <0x86 0x06 0x86 0x22>;
		clock-names = "baudclk", "apb_pclk";
		interrupts = <0x00 0x66 0x04 0x00>;
		reg-shift = <0x02>;
		reg-io-width = <0x04>;
		pinctrl-names = "default";
		pinctrl-0 = <0x8b>;
		status = "disabled";
	};

	i2c@ff3c0000 {
		compatible = "rockchip,rk3399-i2c";
		reg = <0x00 0xff3c0000 0x00 0x1000>;
		assigned-clocks = <0x86 0x09>;
		assigned-clock-rates = <0xbebc200>;
		clocks = <0x86 0x09 0x86 0x1b>;
		clock-names = "i2c", "pclk";
		interrupts = <0x00 0x39 0x04 0x00>;
		pinctrl-names = "default";
		pinctrl-0 = <0x8c>;
		#address-cells = <0x01>;
		#size-cells = <0x00>;
		status = "okay";
		clock-frequency = <0x61a80>;
		i2c-scl-rising-time-ns = <0xa8>;
		i2c-scl-falling-time-ns = <0x04>;

		pmic@1b {
			compatible = "rockchip,rk808";
			reg = <0x1b>;
			interrupt-parent = <0x24>;
			interrupts = <0x0a 0x08>;
			#clock-cells = <0x01>;
			clock-output-names = "xin32k", "rk808-clkout2";
			pinctrl-names = "default";
			pinctrl-0 = <0x8d>;
			rockchip,system-power-controller;
			wakeup-source;
			vcc1-supply = <0x8e>;
			vcc2-supply = <0x8e>;
			vcc3-supply = <0x8e>;
			vcc4-supply = <0x8e>;
			vcc6-supply = <0x8e>;
			vcc7-supply = <0x8e>;
			vcc8-supply = <0x4b>;
			vcc9-supply = <0x8e>;
			vcc10-supply = <0x8e>;
			vcc11-supply = <0x8e>;
			vcc12-supply = <0x4b>;
			vddio-supply = <0x8f>;
			phandle = <0x47>;

			regulators {

				DCDC_REG1 {
					regulator-name = "vdd_center";
					regulator-always-on;
					regulator-boot-on;
					regulator-min-microvolt = <0xb71b0>;
					regulator-max-microvolt = <0x149970>;
					regulator-ramp-delay = <0x1771>;

					regulator-state-mem {
						regulator-off-in-suspend;
					};
				};

				DCDC_REG2 {
					regulator-name = "vdd_cpu_l";
					regulator-always-on;
					regulator-boot-on;
					regulator-min-microvolt = <0xb71b0>;
					regulator-max-microvolt = <0x149970>;
					regulator-ramp-delay = <0x1771>;
					phandle = <0x0d>;

					regulator-state-mem {
						regulator-off-in-suspend;
					};
				};

				DCDC_REG3 {
					regulator-name = "vcc_ddr";
					regulator-always-on;
					regulator-boot-on;

					regulator-state-mem {
						regulator-on-in-suspend;
					};
				};

				DCDC_REG4 {
					regulator-name = "vcc_1v8";
					regulator-always-on;
					regulator-boot-on;
					regulator-min-microvolt = <0x1b7740>;
					regulator-max-microvolt = <0x1b7740>;
					phandle = <0x4c>;

					regulator-state-mem {
						regulator-on-in-suspend;
						regulator-suspend-microvolt = <0x1b7740>;
					};
				};

				LDO_REG1 {
					regulator-name = "vcc1v8_dvp";
					regulator-always-on;
					regulator-boot-on;
					regulator-min-microvolt = <0x1b7740>;
					regulator-max-microvolt = <0x1b7740>;
					phandle = <0xa0>;

					regulator-state-mem {
						regulator-off-in-suspend;
					};
				};

				LDO_REG2 {
					regulator-name = "vcc3v0_touch";
					regulator-min-microvolt = <0x2dc6c0>;
					regulator-max-microvolt = <0x2dc6c0>;
					phandle = <0x97>;

					regulator-state-mem {
						regulator-off-in-suspend;
					};
				};

				LDO_REG3 {
					regulator-name = "vcca_1v8";
					regulator-always-on;
					regulator-boot-on;
					regulator-min-microvolt = <0x1b7740>;
					regulator-max-microvolt = <0x1b7740>;
					phandle = <0x8f>;

					regulator-state-mem {
						regulator-on-in-suspend;
						regulator-suspend-microvolt = <0x1b7740>;
					};
				};

				LDO_REG4 {
					regulator-name = "vcc_sdio";
					regulator-always-on;
					regulator-boot-on;
					regulator-min-microvolt = <0x1b7740>;
					regulator-max-microvolt = <0x2dc6c0>;
					phandle = <0x2e>;

					regulator-state-mem {
						regulator-on-in-suspend;
						regulator-suspend-microvolt = <0x2dc6c0>;
					};
				};

				LDO_REG5 {
					regulator-name = "vcca3v0_codec";
					regulator-always-on;
					regulator-boot-on;
					regulator-min-microvolt = <0x2dc6c0>;
					regulator-max-microvolt = <0x2dc6c0>;

					regulator-state-mem {
						regulator-off-in-suspend;
					};
				};

				LDO_REG6 {
					regulator-name = "vcc_1v5";
					regulator-always-on;
					regulator-boot-on;
					regulator-min-microvolt = <0x16e360>;
					regulator-max-microvolt = <0x16e360>;

					regulator-state-mem {
						regulator-on-in-suspend;
						regulator-suspend-microvolt = <0x16e360>;
					};
				};

				LDO_REG7 {
					regulator-name = "vcca1v8_codec";
					regulator-always-on;
					regulator-boot-on;
					regulator-min-microvolt = <0x1b7740>;
					regulator-max-microvolt = <0x1b7740>;

					regulator-state-mem {
						regulator-off-in-suspend;
					};
				};

				LDO_REG8 {
					regulator-name = "vcc_3v0";
					regulator-always-on;
					regulator-boot-on;
					regulator-min-microvolt = <0x2dc6c0>;
					regulator-max-microvolt = <0x2dc6c0>;
					phandle = <0x85>;

					regulator-state-mem {
						regulator-on-in-suspend;
						regulator-suspend-microvolt = <0x2dc6c0>;
					};
				};

				SWITCH_REG1 {
					regulator-name = "vcc3v3_s3";
					regulator-always-on;
					regulator-boot-on;
					phandle = <0x22>;

					regulator-state-mem {
						regulator-off-in-suspend;
					};
				};

				SWITCH_REG2 {
					regulator-name = "vcc3v3_s0";
					phandle = <0xc4>;

					regulator-state-mem {
						regulator-off-in-suspend;
					};
				};
			};
		};

		regulator@40 {
			compatible = "silergy,syr827";
			reg = <0x40>;
			fcs,suspend-voltage-selector = <0x01>;
			pinctrl-names = "default";
			pinctrl-0 = <0x90>;
			regulator-name = "vdd_cpu_b";
			regulator-min-microvolt = <0xadf34>;
			regulator-max-microvolt = <0x16e360>;
			regulator-ramp-delay = <0x3e8>;
			regulator-always-on;
			regulator-boot-on;
			vin-supply = <0x8e>;
			phandle = <0x10>;

			regulator-state-mem {
				regulator-off-in-suspend;
			};
		};

		regulator@41 {
			compatible = "silergy,syr828";
			reg = <0x41>;
			fcs,suspend-voltage-selector = <0x01>;
			pinctrl-names = "default";
			pinctrl-0 = <0x91>;
			regulator-name = "vdd_gpu";
			regulator-min-microvolt = <0xadf34>;
			regulator-max-microvolt = <0x16e360>;
			regulator-ramp-delay = <0x3e8>;
			regulator-always-on;
			regulator-boot-on;
			vin-supply = <0x8e>;
			phandle = <0xcc>;

			regulator-state-mem {
				regulator-off-in-suspend;
			};
		};
	};

	i2c@ff3d0000 {
		compatible = "rockchip,rk3399-i2c";
		reg = <0x00 0xff3d0000 0x00 0x1000>;
		assigned-clocks = <0x86 0x0a>;
		assigned-clock-rates = <0xbebc200>;
		clocks = <0x86 0x0a 0x86 0x1c>;
		clock-names = "i2c", "pclk";
		interrupts = <0x00 0x38 0x04 0x00>;
		pinctrl-names = "default";
		pinctrl-0 = <0x92>;
		#address-cells = <0x01>;
		#size-cells = <0x00>;
		status = "okay";
		i2c-scl-rising-time-ns = <0x258>;
		i2c-scl-falling-time-ns = <0x14>;

		typec-portc@22 {
			compatible = "fcs,fusb302";
			reg = <0x22>;
			interrupt-parent = <0x93>;
			interrupts = <0x02 0x08>;
			pinctrl-names = "default";
			pinctrl-0 = <0x94>;
			vbus-supply = <0x95>;
			status = "okay";
		};

		touchscreen@5d {
			compatible = "goodix,gt911";
			reg = <0x5d>;
			interrupt-parent = <0x96>;
			interrupts = <0x1d 0x02>;
			AVDD28-supply = <0x97>;
			VDDIO-supply = <0x97>;
			irq-gpios = <0x96 0x1d 0x00>;
			reset-gpios = <0x96 0x1e 0x00>;
			status = "disabled";
		};
	};

	i2c@ff3e0000 {
		compatible = "rockchip,rk3399-i2c";
		reg = <0x00 0xff3e0000 0x00 0x1000>;
		assigned-clocks = <0x86 0x0b>;
		assigned-clock-rates = <0xbebc200>;
		clocks = <0x86 0x0b 0x86 0x1d>;
		clock-names = "i2c", "pclk";
		interrupts = <0x00 0x3a 0x04 0x00>;
		pinctrl-names = "default";
		pinctrl-0 = <0x98>;
		#address-cells = <0x01>;
		#size-cells = <0x00>;
		status = "disabled";
	};

	pwm@ff420000 {
		compatible = "rockchip,rk3399-pwm", "rockchip,rk3288-pwm";
		reg = <0x00 0xff420000 0x00 0x10>;
		#pwm-cells = <0x03>;
		pinctrl-names = "default";
		pinctrl-0 = <0x99>;
		clocks = <0x86 0x1e>;
		status = "okay";
		phandle = <0xd2>;
	};

	pwm@ff420010 {
		compatible = "rockchip,rk3399-pwm", "rockchip,rk3288-pwm";
		reg = <0x00 0xff420010 0x00 0x10>;
		#pwm-cells = <0x03>;
		pinctrl-names = "default";
		pinctrl-0 = <0x9a>;
		clocks = <0x86 0x1e>;
		status = "okay";
		phandle = <0xd7>;
	};

	pwm@ff420020 {
		compatible = "rockchip,rk3399-pwm", "rockchip,rk3288-pwm";
		reg = <0x00 0xff420020 0x00 0x10>;
		#pwm-cells = <0x03>;
		pinctrl-names = "default";
		pinctrl-0 = <0x9b>;
		clocks = <0x86 0x1e>;
		status = "okay";
		phandle = <0xe1>;
	};

	pwm@ff420030 {
		compatible = "rockchip,rk3399-pwm", "rockchip,rk3288-pwm";
		reg = <0x00 0xff420030 0x00 0x10>;
		#pwm-cells = <0x03>;
		pinctrl-names = "default";
		pinctrl-0 = <0x9c>;
		clocks = <0x86 0x1e>;
		status = "disabled";
	};

	dfi@ff630000 {
		reg = <0x00 0xff630000 0x00 0x4000>;
		compatible = "rockchip,rk3399-dfi";
		rockchip,pmu = <0x13>;
		interrupts = <0x00 0x83 0x04 0x00>;
		clocks = <0x08 0x179>;
		clock-names = "pclk_ddr_mon";
		phandle = <0x14>;
	};

	video-codec@ff650000 {
		compatible = "rockchip,rk3399-vpu";
		reg = <0x00 0xff650000 0x00 0x800>;
		interrupts = <0x00 0x72 0x04 0x00 0x00 0x71 0x04 0x00>;
		interrupt-names = "vepu", "vdpu";
		clocks = <0x08 0xeb 0x08 0x1ea>;
		clock-names = "aclk", "hclk";
		iommus = <0x9d>;
		power-domains = <0x1f 0x1f>;
	};

	iommu@ff650800 {
		compatible = "rockchip,iommu";
		reg = <0x00 0xff650800 0x00 0x40>;
		interrupts = <0x00 0x73 0x04 0x00>;
		clocks = <0x08 0xeb 0x08 0x1ea>;
		clock-names = "aclk", "iface";
		#iommu-cells = <0x00>;
		power-domains = <0x1f 0x1f>;
		phandle = <0x9d>;
	};

	video-codec@ff660000 {
		compatible = "rockchip,rk3399-vdec";
		reg = <0x00 0xff660000 0x00 0x480>;
		interrupts = <0x00 0x74 0x04 0x00>;
		clocks = <0x08 0xed 0x08 0x1ec 0x08 0x9f 0x08 0x9e>;
		clock-names = "axi", "ahb", "cabac", "core";
		iommus = <0x9e>;
		power-domains = <0x1f 0x20>;
	};

	iommu@ff660480 {
		compatible = "rockchip,iommu";
		reg = <0x00 0xff660480 0x00 0x40 0x00 0xff6604c0 0x00 0x40>;
		interrupts = <0x00 0x75 0x04 0x00>;
		clocks = <0x08 0xed 0x08 0x1ec>;
		clock-names = "aclk", "iface";
		power-domains = <0x1f 0x20>;
		#iommu-cells = <0x00>;
		phandle = <0x9e>;
	};

	iommu@ff670800 {
		compatible = "rockchip,iommu";
		reg = <0x00 0xff670800 0x00 0x40>;
		interrupts = <0x00 0x2a 0x04 0x00>;
		clocks = <0x08 0xe1 0x08 0x1dd>;
		clock-names = "aclk", "iface";
		#iommu-cells = <0x00>;
		status = "disabled";
	};

	rga@ff680000 {
		compatible = "rockchip,rk3399-rga";
		reg = <0x00 0xff680000 0x00 0x10000>;
		interrupts = <0x00 0x37 0x04 0x00>;
		clocks = <0x08 0xdc 0x08 0x1e5 0x08 0x6d>;
		clock-names = "aclk", "hclk", "sclk";
		resets = <0x08 0x6a 0x08 0x67 0x08 0x69>;
		reset-names = "core", "axi", "ahb";
		power-domains = <0x1f 0x21>;
	};

	efuse@ff690000 {
		compatible = "rockchip,rk3399-efuse";
		reg = <0x00 0xff690000 0x00 0x80>;
		#address-cells = <0x01>;
		#size-cells = <0x01>;
		clocks = <0x08 0x17d>;
		clock-names = "pclk_efuse";

		cpu-id@7 {
			reg = <0x07 0x10>;
		};

		cpu-leakage@17 {
			reg = <0x17 0x01>;
		};

		gpu-leakage@18 {
			reg = <0x18 0x01>;
		};

		center-leakage@19 {
			reg = <0x19 0x01>;
		};

		cpu-leakage@1a {
			reg = <0x1a 0x01>;
		};

		logic-leakage@1b {
			reg = <0x1b 0x01>;
		};

		wafer-info@1c {
			reg = <0x1c 0x01>;
		};
	};

	dma-controller@ff6d0000 {
		compatible = "arm,pl330", "arm,primecell";
		reg = <0x00 0xff6d0000 0x00 0x4000>;
		interrupts = <0x00 0x05 0x04 0x00 0x00 0x06 0x04 0x00>;
		#dma-cells = <0x01>;
		arm,pl330-periph-burst;
		clocks = <0x08 0xd3>;
		clock-names = "apb_pclk";
		phandle = <0x61>;
	};

	dma-controller@ff6e0000 {
		compatible = "arm,pl330", "arm,primecell";
		reg = <0x00 0xff6e0000 0x00 0x4000>;
		interrupts = <0x00 0x07 0x04 0x00 0x00 0x08 0x04 0x00>;
		#dma-cells = <0x01>;
		arm,pl330-periph-burst;
		clocks = <0x08 0xd4>;
		clock-names = "apb_pclk";
		phandle = <0x50>;
	};

	clock-controller@ff750000 {
		compatible = "rockchip,rk3399-pmucru";
		reg = <0x00 0xff750000 0x00 0x1000>;
		clocks = <0x9f>;
		clock-names = "xin24m";
		rockchip,grf = <0x13>;
		#clock-cells = <0x01>;
		#reset-cells = <0x01>;
		assigned-clocks = <0x86 0x01>;
		assigned-clock-rates = <0x284af100>;
		phandle = <0x86>;
	};

	clock-controller@ff760000 {
		compatible = "rockchip,rk3399-cru";
		reg = <0x00 0xff760000 0x00 0x1000>;
		clocks = <0x9f>;
		clock-names = "xin24m";
		rockchip,grf = <0x20>;
		#clock-cells = <0x01>;
		#reset-cells = <0x01>;
		assigned-clocks = <0x08 0x05 0x08 0x04 0x08 0x06 0x08 0xc0 0x08 0x1c0 0x08 0x140 0x08 0xc2 0x08 0x1c1 0x08 0x142 0x08 0xc9 0x08 0x1c2 0x08 0x143 0x08 0xe3 0x08 0xde 0x08 0x106 0x08 0x178 0x08 0xed>;
		assigned-clock-rates = <0x2367b880 0x2faf0800 0x3b9aca00 0x8f0d180 0x47868c0 0x23c3460 0x5f5e100 0x5f5e100 0x2faf080 0x23c34600 0x5f5e100 0x2faf080 0x17d78400 0x17d78400 0xbebc200 0xbebc200 0x17d78400>;
		phandle = <0x08>;
	};

	syscon@ff770000 {
		compatible = "rockchip,rk3399-grf", "syscon", "simple-mfd";
		reg = <0x00 0xff770000 0x00 0x10000>;
		#address-cells = <0x01>;
		#size-cells = <0x01>;
		phandle = <0x20>;

		io-domains {
			compatible = "rockchip,rk3399-io-voltage-domain";
			status = "okay";
			bt656-supply = <0xa0>;
			audio-supply = <0x85>;
			sdmmc-supply = <0x2e>;
			gpio1830-supply = <0x85>;
		};

		mipi-dphy-rx0 {
			compatible = "rockchip,rk3399-mipi-dphy-rx0";
			clocks = <0x08 0x77 0x08 0xa5 0x08 0x16f>;
			clock-names = "dphy-ref", "dphy-cfg", "grf";
			power-domains = <0x1f 0x0f>;
			#phy-cells = <0x00>;
			status = "disabled";
			phandle = <0xb6>;
		};

		usb2phy@e450 {
			compatible = "rockchip,rk3399-usb2phy";
			reg = <0xe450 0x10>;
			clocks = <0x08 0x7b>;
			clock-names = "phyclk";
			#clock-cells = <0x00>;
			clock-output-names = "clk_usbphy0_480m";
			status = "okay";
			phandle = <0x30>;

			host-port {
				#phy-cells = <0x00>;
				interrupts = <0x00 0x1b 0x04 0x00>;
				interrupt-names = "linestate";
				status = "okay";
				phy-supply = <0xa1>;
				phandle = <0x31>;
			};

			otg-port {
				#phy-cells = <0x00>;
				interrupts = <0x00 0x67 0x04 0x00 0x00 0x68 0x04 0x00 0x00 0x6a 0x04 0x00>;
				interrupt-names = "otg-bvalid", "otg-id", "linestate";
				status = "okay";
				phandle = <0x34>;
			};
		};

		usb2phy@e460 {
			compatible = "rockchip,rk3399-usb2phy";
			reg = <0xe460 0x10>;
			clocks = <0x08 0x7c>;
			clock-names = "phyclk";
			#clock-cells = <0x00>;
			clock-output-names = "clk_usbphy1_480m";
			status = "okay";
			phandle = <0x32>;

			host-port {
				#phy-cells = <0x00>;
				interrupts = <0x00 0x1f 0x04 0x00>;
				interrupt-names = "linestate";
				status = "okay";
				phy-supply = <0xa1>;
				phandle = <0x33>;
			};

			otg-port {
				#phy-cells = <0x00>;
				interrupts = <0x00 0x6c 0x04 0x00 0x00 0x6d 0x04 0x00 0x00 0x6f 0x04 0x00>;
				interrupt-names = "otg-bvalid", "otg-id", "linestate";
				status = "okay";
				phandle = <0x36>;
			};
		};

		phy@f780 {
			compatible = "rockchip,rk3399-emmc-phy";
			reg = <0xf780 0x24>;
			clocks = <0xa2>;
			clock-names = "emmcclk";
			drive-impedance-ohm = <0x32>;
			#phy-cells = <0x00>;
			status = "okay";
			phandle = <0x2f>;
		};

		pcie-phy {
			compatible = "rockchip,rk3399-pcie-phy";
			clocks = <0x08 0x8a>;
			clock-names = "refclk";
			#phy-cells = <0x01>;
			resets = <0x08 0x87>;
			reset-names = "phy";
			status = "okay";
			phandle = <0x19>;
		};
	};

	phy@ff7c0000 {
		compatible = "rockchip,rk3399-typec-phy";
		reg = <0x00 0xff7c0000 0x00 0x40000>;
		clocks = <0x08 0x7e 0x08 0x7d>;
		clock-names = "tcpdcore", "tcpdphy-ref";
		assigned-clocks = <0x08 0x7e>;
		assigned-clock-rates = <0x2faf080>;
		power-domains = <0x1f 0x08>;
		resets = <0x08 0x95 0x08 0x94 0x08 0x14c>;
		reset-names = "uphy", "uphy-pipe", "uphy-tcphy";
		rockchip,grf = <0x20>;
		status = "okay";

		dp-port {
			#phy-cells = <0x00>;
			phandle = <0x38>;
		};

		usb3-port {
			#phy-cells = <0x00>;
			phandle = <0x35>;
		};
	};

	phy@ff800000 {
		compatible = "rockchip,rk3399-typec-phy";
		reg = <0x00 0xff800000 0x00 0x40000>;
		clocks = <0x08 0x80 0x08 0x7f>;
		clock-names = "tcpdcore", "tcpdphy-ref";
		assigned-clocks = <0x08 0x80>;
		assigned-clock-rates = <0x2faf080>;
		power-domains = <0x1f 0x09>;
		resets = <0x08 0x9d 0x08 0x9c 0x08 0x14d>;
		reset-names = "uphy", "uphy-pipe", "uphy-tcphy";
		rockchip,grf = <0x20>;
		status = "okay";

		dp-port {
			#phy-cells = <0x00>;
			phandle = <0x39>;
		};

		usb3-port {
			#phy-cells = <0x00>;
			phandle = <0x37>;
		};
	};

	watchdog@ff848000 {
		compatible = "rockchip,rk3399-wdt", "snps,dw-wdt";
		reg = <0x00 0xff848000 0x00 0x100>;
		clocks = <0x08 0x17c>;
		interrupts = <0x00 0x78 0x04 0x00>;
	};

	rktimer@ff850000 {
		compatible = "rockchip,rk3399-timer";
		reg = <0x00 0xff850000 0x00 0x1000>;
		interrupts = <0x00 0x51 0x04 0x00>;
		clocks = <0x08 0x168 0x08 0x5a>;
		clock-names = "pclk", "timer";
	};

	spdif@ff870000 {
		compatible = "rockchip,rk3399-spdif";
		reg = <0x00 0xff870000 0x00 0x1000>;
		interrupts = <0x00 0x42 0x04 0x00>;
		dmas = <0x61 0x07>;
		dma-names = "tx";
		clock-names = "mclk", "hclk";
		clocks = <0x08 0x55 0x08 0x1d7>;
		pinctrl-names = "default";
		pinctrl-0 = <0xa3>;
		power-domains = <0x1f 0x1c>;
		#sound-dai-cells = <0x00>;
		status = "disabled";

		port {
			phandle = <0xda>;

			endpoint {
				remote-endpoint = <0xa4>;
				phandle = <0xdb>;
			};
		};
	};

	i2s@ff880000 {
		compatible = "rockchip,rk3399-i2s", "rockchip,rk3066-i2s";
		reg = <0x00 0xff880000 0x00 0x1000>;
		rockchip,grf = <0x20>;
		interrupts = <0x00 0x27 0x04 0x00>;
		dmas = <0x61 0x00 0x61 0x01>;
		dma-names = "tx", "rx";
		clock-names = "i2s_clk", "i2s_hclk";
		clocks = <0x08 0x56 0x08 0x1d4>;
		pinctrl-names = "bclk_on", "bclk_off";
		pinctrl-0 = <0xa5>;
		pinctrl-1 = <0xa6>;
		power-domains = <0x1f 0x1c>;
		#sound-dai-cells = <0x00>;
		status = "okay";
		rockchip,playback-channels = <0x08>;
		rockchip,capture-channels = <0x08>;
	};

	i2s@ff890000 {
		compatible = "rockchip,rk3399-i2s", "rockchip,rk3066-i2s";
		reg = <0x00 0xff890000 0x00 0x1000>;
		interrupts = <0x00 0x28 0x04 0x00>;
		dmas = <0x61 0x02 0x61 0x03>;
		dma-names = "tx", "rx";
		clock-names = "i2s_clk", "i2s_hclk";
		clocks = <0x08 0x57 0x08 0x1d5>;
		pinctrl-names = "default";
		pinctrl-0 = <0xa7>;
		power-domains = <0x1f 0x1c>;
		#sound-dai-cells = <0x00>;
		status = "okay";
		rockchip,playback-channels = <0x02>;
		rockchip,capture-channels = <0x02>;

		port {
			phandle = <0xd9>;

			endpoint {
				dai-format = "i2s";
				mclk-fs = <0x100>;
				remote-endpoint = <0xa8>;
				phandle = <0x3e>;
			};
		};
	};

	i2s@ff8a0000 {
		compatible = "rockchip,rk3399-i2s", "rockchip,rk3066-i2s";
		reg = <0x00 0xff8a0000 0x00 0x1000>;
		interrupts = <0x00 0x29 0x04 0x00>;
		dmas = <0x61 0x04 0x61 0x05>;
		dma-names = "tx", "rx";
		clock-names = "i2s_clk", "i2s_hclk";
		clocks = <0x08 0x58 0x08 0x1d6>;
		power-domains = <0x1f 0x1c>;
		#sound-dai-cells = <0x00>;
		status = "okay";
		phandle = <0xb9>;
	};

	vop@ff8f0000 {
		compatible = "rockchip,rk3399-vop-lit";
		reg = <0x00 0xff8f0000 0x00 0x2000 0x00 0xff8f2000 0x00 0x400>;
		interrupts = <0x00 0x77 0x04 0x00>;
		assigned-clocks = <0x08 0xdb 0x08 0x1db>;
		assigned-clock-rates = <0x17d78400 0x5f5e100>;
		clocks = <0x08 0xdb 0x08 0xb5 0x08 0x1db>;
		clock-names = "aclk_vop", "dclk_vop", "hclk_vop";
		iommus = <0xa9>;
		power-domains = <0x1f 0x12>;
		resets = <0x08 0x113 0x08 0x117 0x08 0x119>;
		reset-names = "axi", "ahb", "dclk";
		status = "okay";

		port {
			#address-cells = <0x01>;
			#size-cells = <0x00>;
			phandle = <0x11>;

			endpoint@0 {
				reg = <0x00>;
				remote-endpoint = <0xaa>;
				phandle = <0xc0>;
			};

			endpoint@1 {
				reg = <0x01>;
				remote-endpoint = <0xab>;
				phandle = <0xca>;
			};

			endpoint@2 {
				reg = <0x02>;
				remote-endpoint = <0xac>;
				phandle = <0xbe>;
			};

			endpoint@3 {
				reg = <0x03>;
				remote-endpoint = <0xad>;
				phandle = <0xc7>;
			};

			endpoint@4 {
				reg = <0x04>;
				remote-endpoint = <0xae>;
				phandle = <0x3b>;
			};
		};
	};

	iommu@ff8f3f00 {
		compatible = "rockchip,iommu";
		reg = <0x00 0xff8f3f00 0x00 0x100>;
		interrupts = <0x00 0x77 0x04 0x00>;
		clocks = <0x08 0xdb 0x08 0x1db>;
		clock-names = "aclk", "iface";
		power-domains = <0x1f 0x12>;
		#iommu-cells = <0x00>;
		status = "okay";
		phandle = <0xa9>;
	};

	vop@ff900000 {
		compatible = "rockchip,rk3399-vop-big";
		reg = <0x00 0xff900000 0x00 0x2000 0x00 0xff902000 0x00 0x1000>;
		interrupts = <0x00 0x76 0x04 0x00>;
		assigned-clocks = <0x08 0xd9 0x08 0x1d9>;
		assigned-clock-rates = <0x17d78400 0x5f5e100>;
		clocks = <0x08 0xd9 0x08 0xb4 0x08 0x1d9>;
		clock-names = "aclk_vop", "dclk_vop", "hclk_vop";
		iommus = <0xaf>;
		power-domains = <0x1f 0x11>;
		resets = <0x08 0x112 0x08 0x116 0x08 0x118>;
		reset-names = "axi", "ahb", "dclk";
		status = "okay";

		port {
			#address-cells = <0x01>;
			#size-cells = <0x00>;
			phandle = <0x12>;

			endpoint@0 {
				reg = <0x00>;
				remote-endpoint = <0xb0>;
				phandle = <0xc9>;
			};

			endpoint@1 {
				reg = <0x01>;
				remote-endpoint = <0xb1>;
				phandle = <0xbf>;
			};

			endpoint@2 {
				reg = <0x02>;
				remote-endpoint = <0xb2>;
				phandle = <0xbd>;
			};

			endpoint@3 {
				reg = <0x03>;
				remote-endpoint = <0xb3>;
				phandle = <0xc6>;
			};

			endpoint@4 {
				reg = <0x04>;
				remote-endpoint = <0xb4>;
				phandle = <0x3a>;
			};
		};
	};

	iommu@ff903f00 {
		compatible = "rockchip,iommu";
		reg = <0x00 0xff903f00 0x00 0x100>;
		interrupts = <0x00 0x76 0x04 0x00>;
		clocks = <0x08 0xd9 0x08 0x1d9>;
		clock-names = "aclk", "iface";
		power-domains = <0x1f 0x11>;
		#iommu-cells = <0x00>;
		status = "okay";
		phandle = <0xaf>;
	};

	isp0@ff910000 {
		compatible = "rockchip,rk3399-cif-isp";
		reg = <0x00 0xff910000 0x00 0x4000>;
		interrupts = <0x00 0x2b 0x04 0x00>;
		clocks = <0x08 0x6e 0x08 0xe9 0x08 0x1e3>;
		clock-names = "isp", "aclk", "hclk";
		iommus = <0xb5>;
		phys = <0xb6>;
		phy-names = "dphy";
		power-domains = <0x1f 0x13>;
		status = "disabled";

		ports {
			#address-cells = <0x01>;
			#size-cells = <0x00>;

			port@0 {
				reg = <0x00>;
				#address-cells = <0x01>;
				#size-cells = <0x00>;
			};
		};
	};

	iommu@ff914000 {
		compatible = "rockchip,iommu";
		reg = <0x00 0xff914000 0x00 0x100 0x00 0xff915000 0x00 0x100>;
		interrupts = <0x00 0x2b 0x04 0x00>;
		clocks = <0x08 0xe9 0x08 0x1e3>;
		clock-names = "aclk", "iface";
		#iommu-cells = <0x00>;
		power-domains = <0x1f 0x13>;
		rockchip,disable-mmu-reset;
		phandle = <0xb5>;
	};

	isp1@ff920000 {
		compatible = "rockchip,rk3399-cif-isp";
		reg = <0x00 0xff920000 0x00 0x4000>;
		interrupts = <0x00 0x2c 0x04 0x00>;
		clocks = <0x08 0x6f 0x08 0xea 0x08 0x1e4>;
		clock-names = "isp", "aclk", "hclk";
		iommus = <0xb7>;
		phys = <0xb8>;
		phy-names = "dphy";
		power-domains = <0x1f 0x14>;
		status = "disabled";

		ports {
			#address-cells = <0x01>;
			#size-cells = <0x00>;

			port@0 {
				reg = <0x00>;
				#address-cells = <0x01>;
				#size-cells = <0x00>;
			};
		};
	};

	iommu@ff924000 {
		compatible = "rockchip,iommu";
		reg = <0x00 0xff924000 0x00 0x100 0x00 0xff925000 0x00 0x100>;
		interrupts = <0x00 0x2c 0x04 0x00>;
		clocks = <0x08 0xea 0x08 0x1e4>;
		clock-names = "aclk", "iface";
		#iommu-cells = <0x00>;
		power-domains = <0x1f 0x14>;
		rockchip,disable-mmu-reset;
		phandle = <0xb7>;
	};

	hdmi-sound {
		compatible = "simple-audio-card";
		simple-audio-card,format = "i2s";
		simple-audio-card,mclk-fs = <0x100>;
		simple-audio-card,name = "hdmi-sound";
		status = "okay";

		simple-audio-card,cpu {
			sound-dai = <0xb9>;
		};

		simple-audio-card,codec {
			sound-dai = <0xba>;
		};
	};

	hdmi@ff940000 {
		compatible = "rockchip,rk3399-dw-hdmi";
		reg = <0x00 0xff940000 0x00 0x20000>;
		reg-io-width = <0x04>;
		interrupts = <0x00 0x17 0x04 0x00>;
		clocks = <0x08 0x174 0x08 0x71 0x08 0x70 0x08 0x16f 0x08 0x07>;
		clock-names = "iahb", "isfr", "cec", "grf", "ref";
		power-domains = <0x1f 0x15>;
		rockchip,grf = <0x20>;
		#sound-dai-cells = <0x00>;
		status = "okay";
		ddc-i2c-bus = <0xbb>;
		pinctrl-names = "default";
		pinctrl-0 = <0xbc>;
		phandle = <0xba>;

		ports {
			#address-cells = <0x01>;
			#size-cells = <0x00>;

			port@0 {
				reg = <0x00>;
				#address-cells = <0x01>;
				#size-cells = <0x00>;

				endpoint@0 {
					reg = <0x00>;
					remote-endpoint = <0xbd>;
					phandle = <0xb2>;
				};

				endpoint@1 {
					reg = <0x01>;
					remote-endpoint = <0xbe>;
					phandle = <0xac>;
				};
			};

			port@1 {
				reg = <0x01>;
			};
		};
	};

	dsi@ff960000 {
		compatible = "rockchip,rk3399-mipi-dsi", "snps,dw-mipi-dsi";
		reg = <0x00 0xff960000 0x00 0x8000>;
		interrupts = <0x00 0x2d 0x04 0x00>;
		clocks = <0x08 0xa2 0x08 0x170 0x08 0xa3 0x08 0x16f>;
		clock-names = "ref", "pclk", "phy_cfg", "grf";
		power-domains = <0x1f 0x0f>;
		resets = <0x08 0xfb>;
		reset-names = "apb";
		rockchip,grf = <0x20>;
		#address-cells = <0x01>;
		#size-cells = <0x00>;
		status = "disabled";
		clock-master;

		ports {
			#address-cells = <0x01>;
			#size-cells = <0x00>;

			port@0 {
				reg = <0x00>;
				#address-cells = <0x01>;
				#size-cells = <0x00>;

				endpoint@0 {
					reg = <0x00>;
					remote-endpoint = <0xbf>;
					phandle = <0xb1>;
				};

				endpoint@1 {
					reg = <0x01>;
					remote-endpoint = <0xc0>;
					phandle = <0xaa>;
				};
			};

			port@1 {
				reg = <0x01>;

				endpoint {
					remote-endpoint = <0xc1>;
					phandle = <0xc5>;
				};
			};
		};

		panel@0 {
			compatible = "feiyang,fy07024di26a30d";
			reg = <0x00>;
			avdd-supply = <0xc2>;
			backlight = <0xc3>;
			dvdd-supply = <0xc4>;

			port {

				endpoint {
					remote-endpoint = <0xc5>;
					phandle = <0xc1>;
				};
			};
		};
	};

	dsi@ff968000 {
		compatible = "rockchip,rk3399-mipi-dsi", "snps,dw-mipi-dsi";
		reg = <0x00 0xff968000 0x00 0x8000>;
		interrupts = <0x00 0x2e 0x04 0x00>;
		clocks = <0x08 0xa2 0x08 0x171 0x08 0xa4 0x08 0x16f>;
		clock-names = "ref", "pclk", "phy_cfg", "grf";
		power-domains = <0x1f 0x0f>;
		resets = <0x08 0xfc>;
		reset-names = "apb";
		rockchip,grf = <0x20>;
		#address-cells = <0x01>;
		#size-cells = <0x00>;
		#phy-cells = <0x00>;
		status = "disabled";
		phandle = <0xb8>;

		ports {
			#address-cells = <0x01>;
			#size-cells = <0x00>;

			port@0 {
				reg = <0x00>;
				#address-cells = <0x01>;
				#size-cells = <0x00>;

				endpoint@0 {
					reg = <0x00>;
					remote-endpoint = <0xc6>;
					phandle = <0xb3>;
				};

				endpoint@1 {
					reg = <0x01>;
					remote-endpoint = <0xc7>;
					phandle = <0xad>;
				};
			};

			port@1 {
				reg = <0x01>;
			};
		};
	};

	dp@ff970000 {
		compatible = "rockchip,rk3399-edp";
		reg = <0x00 0xff970000 0x00 0x8000>;
		interrupts = <0x00 0x0a 0x04 0x00>;
		clocks = <0x08 0x16a 0x08 0x16c 0x08 0x16f>;
		clock-names = "dp", "pclk", "grf";
		pinctrl-names = "default";
		pinctrl-0 = <0xc8>;
		power-domains = <0x1f 0x19>;
		resets = <0x08 0x11d>;
		reset-names = "dp";
		rockchip,grf = <0x20>;
		status = "disabled";

		ports {
			#address-cells = <0x01>;
			#size-cells = <0x00>;

			port@0 {
				reg = <0x00>;
				#address-cells = <0x01>;
				#size-cells = <0x00>;

				endpoint@0 {
					reg = <0x00>;
					remote-endpoint = <0xc9>;
					phandle = <0xb0>;
				};

				endpoint@1 {
					reg = <0x01>;
					remote-endpoint = <0xca>;
					phandle = <0xab>;
				};
			};

			port@1 {
				reg = <0x01>;
			};
		};
	};

	gpu@ff9a0000 {
		compatible = "rockchip,rk3399-mali", "arm,mali-t860";
		reg = <0x00 0xff9a0000 0x00 0x10000>;
		interrupts = <0x00 0x14 0x04 0x00 0x00 0x15 0x04 0x00 0x00 0x13 0x04 0x00>;
		interrupt-names = "job", "mmu", "gpu";
		clocks = <0x08 0xd0>;
		#cooling-cells = <0x02>;
		dynamic-power-coefficient = <0xa50>;
		power-domains = <0x1f 0x23>;
		status = "okay";
		operating-points-v2 = <0xcb>;
		mali-supply = <0xcc>;
		phandle = <0x6d>;
	};

	pinctrl {
		compatible = "rockchip,rk3399-pinctrl";
		rockchip,grf = <0x20>;
		rockchip,pmu = <0x13>;
		#address-cells = <0x02>;
		#size-cells = <0x02>;
		ranges;

		gpio@ff720000 {
			compatible = "rockchip,gpio-bank";
			reg = <0x00 0xff720000 0x00 0x100>;
			clocks = <0x86 0x17>;
			interrupts = <0x00 0x0e 0x04 0x00>;
			gpio-controller;
			#gpio-cells = <0x02>;
			interrupt-controller;
			#interrupt-cells = <0x02>;
			phandle = <0x29>;
		};

		gpio@ff730000 {
			compatible = "rockchip,gpio-bank";
			reg = <0x00 0xff730000 0x00 0x100>;
			clocks = <0x86 0x18>;
			interrupts = <0x00 0x0f 0x04 0x00>;
			gpio-controller;
			#gpio-cells = <0x02>;
			interrupt-controller;
			#interrupt-cells = <0x02>;
			phandle = <0x93>;
		};

		gpio@ff780000 {
			compatible = "rockchip,gpio-bank";
			reg = <0x00 0xff780000 0x00 0x100>;
			clocks = <0x08 0x150>;
			interrupts = <0x00 0x10 0x04 0x00>;
			gpio-controller;
			#gpio-cells = <0x02>;
			interrupt-controller;
			#interrupt-cells = <0x02>;
			phandle = <0x1a>;
		};

		gpio@ff788000 {
			compatible = "rockchip,gpio-bank";
			reg = <0x00 0xff788000 0x00 0x100>;
			clocks = <0x08 0x151>;
			interrupts = <0x00 0x11 0x04 0x00>;
			gpio-controller;
			#gpio-cells = <0x02>;
			interrupt-controller;
			#interrupt-cells = <0x02>;
			phandle = <0x24>;
		};

		gpio@ff790000 {
			compatible = "rockchip,gpio-bank";
			reg = <0x00 0xff790000 0x00 0x100>;
			clocks = <0x08 0x152>;
			interrupts = <0x00 0x12 0x04 0x00>;
			gpio-controller;
			#gpio-cells = <0x02>;
			interrupt-controller;
			#interrupt-cells = <0x02>;
			phandle = <0x96>;
		};

		pcfg-pull-up {
			bias-pull-up;
			phandle = <0xd0>;
		};

		pcfg-pull-down {
			bias-pull-down;
			phandle = <0xd1>;
		};

		pcfg-pull-none {
			bias-disable;
			phandle = <0xcd>;
		};

		pcfg-pull-none-12ma {
			bias-disable;
			drive-strength = <0x0c>;
			phandle = <0xcf>;
		};

		pcfg-pull-none-13ma {
			bias-disable;
			drive-strength = <0x0d>;
			phandle = <0xce>;
		};

		pcfg-pull-none-18ma {
			bias-disable;
			drive-strength = <0x12>;
		};

		pcfg-pull-none-20ma {
			bias-disable;
			drive-strength = <0x14>;
		};

		pcfg-pull-up-2ma {
			bias-pull-up;
			drive-strength = <0x02>;
		};

		pcfg-pull-up-8ma {
			bias-pull-up;
			drive-strength = <0x08>;
		};

		pcfg-pull-up-18ma {
			bias-pull-up;
			drive-strength = <0x12>;
		};

		pcfg-pull-up-20ma {
			bias-pull-up;
			drive-strength = <0x14>;
		};

		pcfg-pull-down-4ma {
			bias-pull-down;
			drive-strength = <0x04>;
		};

		pcfg-pull-down-8ma {
			bias-pull-down;
			drive-strength = <0x08>;
		};

		pcfg-pull-down-12ma {
			bias-pull-down;
			drive-strength = <0x0c>;
		};

		pcfg-pull-down-18ma {
			bias-pull-down;
			drive-strength = <0x12>;
		};

		pcfg-pull-down-20ma {
			bias-pull-down;
			drive-strength = <0x14>;
		};

		pcfg-output-high {
			output-high;
		};

		pcfg-output-low {
			output-low;
		};

		pcfg-input-enable {
			input-enable;
		};

		pcfg-input-pull-up {
			input-enable;
			bias-pull-up;
		};

		pcfg-input-pull-down {
			input-enable;
			bias-pull-down;
		};

		clock {

			clk-32k {
				rockchip,pins = <0x00 0x00 0x02 0xcd>;
			};
		};

		cif {

			cif-clkin {
				rockchip,pins = <0x02 0x0a 0x03 0xcd>;
			};

			cif-clkouta {
				rockchip,pins = <0x02 0x0b 0x03 0xcd>;
			};
		};

		edp {

			edp-hpd {
				rockchip,pins = <0x04 0x17 0x02 0xcd>;
				phandle = <0xc8>;
			};
		};

		gmac {

			rgmii-pins {
				rockchip,pins = <0x03 0x11 0x01 0xce 0x03 0x0e 0x01 0xcd 0x03 0x0d 0x01 0xcd 0x03 0x0c 0x01 0xce 0x03 0x0b 0x01 0xcd 0x03 0x09 0x01 0xcd 0x03 0x08 0x01 0xcd 0x03 0x07 0x01 0xcd 0x03 0x06 0x01 0xcd 0x03 0x05 0x01 0xce 0x03 0x04 0x01 0xce 0x03 0x03 0x01 0xcd 0x03 0x02 0x01 0xcd 0x03 0x01 0x01 0xce 0x03 0x00 0x01 0xce>;
				phandle = <0x23>;
			};

			rmii-pins {
				rockchip,pins = <0x03 0x0d 0x01 0xcd 0x03 0x0c 0x01 0xce 0x03 0x0b 0x01 0xcd 0x03 0x0a 0x01 0xcd 0x03 0x09 0x01 0xcd 0x03 0x08 0x01 0xcd 0x03 0x07 0x01 0xcd 0x03 0x06 0x01 0xcd 0x03 0x05 0x01 0xce 0x03 0x04 0x01 0xce>;
			};
		};

		i2c0 {

			i2c0-xfer {
				rockchip,pins = <0x01 0x0f 0x02 0xcd 0x01 0x10 0x02 0xcd>;
				phandle = <0x8c>;
			};
		};

		i2c1 {

			i2c1-xfer {
				rockchip,pins = <0x04 0x02 0x01 0xcd 0x04 0x01 0x01 0xcd>;
				phandle = <0x3d>;
			};
		};

		i2c2 {

			i2c2-xfer {
				rockchip,pins = <0x02 0x01 0x02 0xcf 0x02 0x00 0x02 0xcf>;
				phandle = <0x3f>;
			};
		};

		i2c3 {

			i2c3-xfer {
				rockchip,pins = <0x04 0x11 0x01 0xcd 0x04 0x10 0x01 0xcd>;
				phandle = <0x40>;
			};
		};

		i2c4 {

			i2c4-xfer {
				rockchip,pins = <0x01 0x0c 0x01 0xcd 0x01 0x0b 0x01 0xcd>;
				phandle = <0x92>;
			};
		};

		i2c5 {

			i2c5-xfer {
				rockchip,pins = <0x03 0x0b 0x02 0xcd 0x03 0x0a 0x02 0xcd>;
				phandle = <0x41>;
			};
		};

		i2c6 {

			i2c6-xfer {
				rockchip,pins = <0x02 0x0a 0x02 0xcd 0x02 0x09 0x02 0xcd>;
				phandle = <0x42>;
			};
		};

		i2c7 {

			i2c7-xfer {
				rockchip,pins = <0x02 0x08 0x02 0xcd 0x02 0x07 0x02 0xcd>;
				phandle = <0x43>;
			};
		};

		i2c8 {

			i2c8-xfer {
				rockchip,pins = <0x01 0x15 0x01 0xcd 0x01 0x14 0x01 0xcd>;
				phandle = <0x98>;
			};
		};

		i2s0 {

			i2s0-2ch-bus {
				rockchip,pins = <0x03 0x18 0x01 0xcd 0x03 0x19 0x01 0xcd 0x03 0x1a 0x01 0xcd 0x03 0x1b 0x01 0xcd 0x03 0x1f 0x01 0xcd 0x04 0x00 0x01 0xcd>;
			};

			i2s0-2ch-bus-bclk-off {
				rockchip,pins = <0x03 0x18 0x00 0xcd 0x03 0x19 0x01 0xcd 0x03 0x1a 0x01 0xcd 0x03 0x1b 0x01 0xcd 0x03 0x1f 0x01 0xcd 0x04 0x00 0x01 0xcd>;
			};

			i2s0-8ch-bus {
				rockchip,pins = <0x03 0x18 0x01 0xcd 0x03 0x19 0x01 0xcd 0x03 0x1a 0x01 0xcd 0x03 0x1b 0x01 0xcd 0x03 0x1c 0x01 0xcd 0x03 0x1d 0x01 0xcd 0x03 0x1e 0x01 0xcd 0x03 0x1f 0x01 0xcd 0x04 0x00 0x01 0xcd>;
				phandle = <0xa5>;
			};

			i2s0-8ch-bus-bclk-off {
				rockchip,pins = <0x03 0x18 0x00 0xcd 0x03 0x19 0x01 0xcd 0x03 0x1a 0x01 0xcd 0x03 0x1b 0x01 0xcd 0x03 0x1c 0x01 0xcd 0x03 0x1d 0x01 0xcd 0x03 0x1e 0x01 0xcd 0x03 0x1f 0x01 0xcd 0x04 0x00 0x01 0xcd>;
				phandle = <0xa6>;
			};
		};

		i2s1 {

			i2s1-2ch-bus {
				rockchip,pins = <0x04 0x03 0x01 0xcd 0x04 0x04 0x01 0xcd 0x04 0x05 0x01 0xcd 0x04 0x06 0x01 0xcd 0x04 0x07 0x01 0xcd>;
				phandle = <0xa7>;
			};

			i2s1-2ch-bus-bclk-off {
				rockchip,pins = <0x04 0x03 0x00 0xcd 0x04 0x04 0x01 0xcd 0x04 0x05 0x01 0xcd 0x04 0x06 0x01 0xcd 0x04 0x07 0x01 0xcd>;
			};
		};

		sdio0 {

			sdio0-bus1 {
				rockchip,pins = <0x02 0x14 0x01 0xd0>;
			};

			sdio0-bus4 {
				rockchip,pins = <0x02 0x14 0x01 0xd0 0x02 0x15 0x01 0xd0 0x02 0x16 0x01 0xd0 0x02 0x17 0x01 0xd0>;
				phandle = <0x26>;
			};

			sdio0-cmd {
				rockchip,pins = <0x02 0x18 0x01 0xd0>;
				phandle = <0x27>;
			};

			sdio0-clk {
				rockchip,pins = <0x02 0x19 0x01 0xcd>;
				phandle = <0x28>;
			};

			sdio0-cd {
				rockchip,pins = <0x02 0x1a 0x01 0xd0>;
			};

			sdio0-pwr {
				rockchip,pins = <0x02 0x1b 0x01 0xd0>;
			};

			sdio0-bkpwr {
				rockchip,pins = <0x02 0x1c 0x01 0xd0>;
			};

			sdio0-wp {
				rockchip,pins = <0x00 0x03 0x01 0xd0>;
			};

			sdio0-int {
				rockchip,pins = <0x00 0x04 0x01 0xd0>;
			};
		};

		sdmmc {

			sdmmc-bus1 {
				rockchip,pins = <0x04 0x08 0x01 0xd0>;
			};

			sdmmc-bus4 {
				rockchip,pins = <0x04 0x08 0x01 0xd0 0x04 0x09 0x01 0xd0 0x04 0x0a 0x01 0xd0 0x04 0x0b 0x01 0xd0>;
				phandle = <0x2c>;
			};

			sdmmc-clk {
				rockchip,pins = <0x04 0x0c 0x01 0xcd>;
				phandle = <0x2a>;
			};

			sdmmc-cmd {
				rockchip,pins = <0x04 0x0d 0x01 0xd0>;
				phandle = <0x2b>;
			};

			sdmmc-cd {
				rockchip,pins = <0x00 0x07 0x01 0xd0>;
			};

			sdmmc-wp {
				rockchip,pins = <0x00 0x08 0x01 0xd0>;
			};
		};

		suspend {

			ap-pwroff {
				rockchip,pins = <0x01 0x05 0x01 0xcd>;
			};

			ddrio-pwroff {
				rockchip,pins = <0x00 0x01 0x01 0xcd>;
			};
		};

		spdif {

			spdif-bus {
				rockchip,pins = <0x04 0x15 0x01 0xcd>;
			};

			spdif-bus-1 {
				rockchip,pins = <0x03 0x10 0x03 0xcd>;
				phandle = <0xa3>;
			};
		};

		spi0 {

			spi0-clk {
				rockchip,pins = <0x03 0x06 0x02 0xd0>;
				phandle = <0x51>;
			};

			spi0-cs0 {
				rockchip,pins = <0x03 0x07 0x02 0xd0>;
				phandle = <0x54>;
			};

			spi0-cs1 {
				rockchip,pins = <0x03 0x08 0x02 0xd0>;
			};

			spi0-tx {
				rockchip,pins = <0x03 0x05 0x02 0xd0>;
				phandle = <0x52>;
			};

			spi0-rx {
				rockchip,pins = <0x03 0x04 0x02 0xd0>;
				phandle = <0x53>;
			};
		};

		spi1 {

			spi1-clk {
				rockchip,pins = <0x01 0x09 0x02 0xd0>;
				phandle = <0x55>;
			};

			spi1-cs0 {
				rockchip,pins = <0x01 0x0a 0x02 0xd0>;
				phandle = <0x58>;
			};

			spi1-rx {
				rockchip,pins = <0x01 0x07 0x02 0xd0>;
				phandle = <0x57>;
			};

			spi1-tx {
				rockchip,pins = <0x01 0x08 0x02 0xd0>;
				phandle = <0x56>;
			};
		};

		spi2 {

			spi2-clk {
				rockchip,pins = <0x02 0x0b 0x01 0xd0>;
				phandle = <0x59>;
			};

			spi2-cs0 {
				rockchip,pins = <0x02 0x0c 0x01 0xd0>;
				phandle = <0x5c>;
			};

			spi2-rx {
				rockchip,pins = <0x02 0x09 0x01 0xd0>;
				phandle = <0x5b>;
			};

			spi2-tx {
				rockchip,pins = <0x02 0x0a 0x01 0xd0>;
				phandle = <0x5a>;
			};
		};

		spi3 {

			spi3-clk {
				rockchip,pins = <0x01 0x11 0x01 0xd0>;
				phandle = <0x87>;
			};

			spi3-cs0 {
				rockchip,pins = <0x01 0x12 0x01 0xd0>;
				phandle = <0x8a>;
			};

			spi3-rx {
				rockchip,pins = <0x01 0x0f 0x01 0xd0>;
				phandle = <0x89>;
			};

			spi3-tx {
				rockchip,pins = <0x01 0x10 0x01 0xd0>;
				phandle = <0x88>;
			};
		};

		spi4 {

			spi4-clk {
				rockchip,pins = <0x03 0x02 0x02 0xd0>;
				phandle = <0x5d>;
			};

			spi4-cs0 {
				rockchip,pins = <0x03 0x03 0x02 0xd0>;
				phandle = <0x60>;
			};

			spi4-rx {
				rockchip,pins = <0x03 0x00 0x02 0xd0>;
				phandle = <0x5f>;
			};

			spi4-tx {
				rockchip,pins = <0x03 0x01 0x02 0xd0>;
				phandle = <0x5e>;
			};
		};

		spi5 {

			spi5-clk {
				rockchip,pins = <0x02 0x16 0x02 0xd0>;
				phandle = <0x62>;
			};

			spi5-cs0 {
				rockchip,pins = <0x02 0x17 0x02 0xd0>;
				phandle = <0x65>;
			};

			spi5-rx {
				rockchip,pins = <0x02 0x14 0x02 0xd0>;
				phandle = <0x64>;
			};

			spi5-tx {
				rockchip,pins = <0x02 0x15 0x02 0xd0>;
				phandle = <0x63>;
			};
		};

		testclk {

			test-clkout0 {
				rockchip,pins = <0x00 0x00 0x01 0xcd>;
			};

			test-clkout1 {
				rockchip,pins = <0x02 0x19 0x02 0xcd>;
			};

			test-clkout2 {
				rockchip,pins = <0x00 0x08 0x03 0xcd>;
			};
		};

		tsadc {

			otp-pin {
				rockchip,pins = <0x01 0x06 0x00 0xcd>;
				phandle = <0x6e>;
			};

			otp-out {
				rockchip,pins = <0x01 0x06 0x01 0xcd>;
				phandle = <0x6f>;
			};
		};

		uart0 {

			uart0-xfer {
				rockchip,pins = <0x02 0x10 0x01 0xd0 0x02 0x11 0x01 0xcd>;
				phandle = <0x44>;
			};

			uart0-cts {
				rockchip,pins = <0x02 0x12 0x01 0xcd>;
				phandle = <0x45>;
			};

			uart0-rts {
				rockchip,pins = <0x02 0x13 0x01 0xcd>;
				phandle = <0x46>;
			};
		};

		uart1 {

			uart1-xfer {
				rockchip,pins = <0x03 0x0c 0x02 0xd0 0x03 0x0d 0x02 0xcd>;
				phandle = <0x4d>;
			};
		};

		uart2a {

			uart2a-xfer {
				rockchip,pins = <0x04 0x08 0x02 0xd0 0x04 0x09 0x02 0xcd>;
			};
		};

		uart2b {

			uart2b-xfer {
				rockchip,pins = <0x04 0x10 0x02 0xd0 0x04 0x11 0x02 0xcd>;
			};
		};

		uart2c {

			uart2c-xfer {
				rockchip,pins = <0x04 0x13 0x01 0xd0 0x04 0x14 0x01 0xcd>;
				phandle = <0x4e>;
			};
		};

		uart3 {

			uart3-xfer {
				rockchip,pins = <0x03 0x0e 0x02 0xd0 0x03 0x0f 0x02 0xcd>;
				phandle = <0x4f>;
			};

			uart3-cts {
				rockchip,pins = <0x03 0x10 0x02 0xcd>;
			};

			uart3-rts {
				rockchip,pins = <0x03 0x11 0x02 0xcd>;
			};
		};

		uart4 {

			uart4-xfer {
				rockchip,pins = <0x01 0x07 0x01 0xd0 0x01 0x08 0x01 0xcd>;
				phandle = <0x8b>;
			};
		};

		uarthdcp {

			uarthdcp-xfer {
				rockchip,pins = <0x04 0x15 0x02 0xd0 0x04 0x16 0x02 0xcd>;
			};
		};

		pwm0 {

			pwm0-pin {
				rockchip,pins = <0x04 0x12 0x01 0xcd>;
				phandle = <0x99>;
			};

			pwm0-pin-pull-down {
				rockchip,pins = <0x04 0x12 0x01 0xd1>;
			};

			vop0-pwm-pin {
				rockchip,pins = <0x04 0x12 0x02 0xcd>;
			};

			vop1-pwm-pin {
				rockchip,pins = <0x04 0x12 0x03 0xcd>;
			};
		};

		pwm1 {

			pwm1-pin {
				rockchip,pins = <0x04 0x16 0x01 0xcd>;
				phandle = <0x9a>;
			};

			pwm1-pin-pull-down {
				rockchip,pins = <0x04 0x16 0x01 0xd1>;
			};
		};

		pwm2 {

			pwm2-pin {
				rockchip,pins = <0x01 0x13 0x01 0xcd>;
				phandle = <0x9b>;
			};

			pwm2-pin-pull-down {
				rockchip,pins = <0x01 0x13 0x01 0xd1>;
			};
		};

		pwm3a {

			pwm3a-pin {
				rockchip,pins = <0x00 0x06 0x01 0xcd>;
				phandle = <0x9c>;
			};
		};

		pwm3b {

			pwm3b-pin {
				rockchip,pins = <0x01 0x0e 0x01 0xcd>;
			};
		};

		hdmi {

			hdmi-i2c-xfer {
				rockchip,pins = <0x04 0x11 0x03 0xcd 0x04 0x10 0x03 0xcd>;
			};

			hdmi-cec {
				rockchip,pins = <0x04 0x17 0x01 0xcd>;
				phandle = <0xbc>;
			};
		};

		pcie {

			pci-clkreqn-cpm {
				rockchip,pins = <0x02 0x1a 0x00 0xcd>;
			};

			pci-clkreqnb-cpm {
				rockchip,pins = <0x04 0x18 0x00 0xcd>;
				phandle = <0x1e>;
			};

			pcie-perst {
				rockchip,pins = <0x02 0x1c 0x00 0xcd>;
				phandle = <0x1b>;
			};

			pcie-pwr-en {
				rockchip,pins = <0x01 0x18 0x00 0xcd>;
				phandle = <0xdd>;
			};
		};

		bt {

			bt-enable-h {
				rockchip,pins = <0x00 0x09 0x00 0xcd>;
				phandle = <0x4a>;
			};

			bt-host-wake-l {
				rockchip,pins = <0x00 0x04 0x00 0xd1>;
				phandle = <0x48>;
			};

			bt-wake-l {
				rockchip,pins = <0x02 0x1b 0x00 0xcd>;
				phandle = <0x49>;
			};
		};

		buttons {

			pwrbtn {
				rockchip,pins = <0x00 0x05 0x00 0xd0>;
				phandle = <0xd3>;
			};
		};

		fusb302x {

			fusb0-int {
				rockchip,pins = <0x01 0x02 0x00 0xd0>;
				phandle = <0x94>;
			};
		};

		ir {

			ir-int {
				rockchip,pins = <0x00 0x06 0x00 0xcd>;
				phandle = <0xd4>;
			};
		};

		leds {

			work-led-pin {
				rockchip,pins = <0x00 0x0b 0x00 0xcd>;
				phandle = <0xd5>;
			};

			diy-led-pin {
				rockchip,pins = <0x00 0x02 0x00 0xcd>;
				phandle = <0xd6>;
			};
		};

		pmic {

			pmic-int-l {
				rockchip,pins = <0x03 0x0a 0x00 0xd0>;
				phandle = <0x8d>;
			};

			vsel1-pin {
				rockchip,pins = <0x01 0x11 0x00 0xd1>;
				phandle = <0x90>;
			};

			vsel2-pin {
				rockchip,pins = <0x01 0x0e 0x00 0xd1>;
				phandle = <0x91>;
			};
		};

		sdcard {

			sdmmc0-pwr-h {
				rockchip,pins = <0x00 0x01 0x00 0xcd>;
				phandle = <0xdc>;
			};
		};

		sdio-pwrseq {

			wifi-enable-h {
				rockchip,pins = <0x00 0x0a 0x00 0xcd>;
				phandle = <0xd8>;
			};
		};

		usb-typec {

			vcc5v0_typec_en {
				rockchip,pins = <0x01 0x03 0x00 0xd0>;
				phandle = <0xe0>;
			};
		};

		usb2 {

			vcc5v0-host-en {
				rockchip,pins = <0x04 0x1a 0x00 0xcd>;
				phandle = <0xde>;
			};
		};
	};

	opp-table-0 {
		compatible = "operating-points-v2";
		opp-shared;
		phandle = <0x0c>;

		opp00 {
			opp-hz = <0x00 0x18519600>;
			opp-microvolt = <0xc96a8 0xc96a8 0x1312d0>;
			clock-latency-ns = <0x9c40>;
		};

		opp01 {
			opp-hz = <0x00 0x23c34600>;
			opp-microvolt = <0xc96a8 0xc96a8 0x1312d0>;
		};

		opp02 {
			opp-hz = <0x00 0x30a32c00>;
			opp-microvolt = <0xcf850 0xcf850 0x1312d0>;
		};

		opp03 {
			opp-hz = <0x00 0x3c14dc00>;
			opp-microvolt = <0xe1d48 0xe1d48 0x1312d0>;
		};

		opp04 {
			opp-hz = <0x00 0x47868c00>;
			opp-microvolt = <0xf4240 0xf4240 0x1312d0>;
		};

		opp05 {
			opp-hz = <0x00 0x54667200>;
			opp-microvolt = <0x112a88 0x112a88 0x1312d0>;
		};
	};

	opp-table-1 {
		compatible = "operating-points-v2";
		opp-shared;
		phandle = <0x0f>;

		opp00 {
			opp-hz = <0x00 0x18519600>;
			opp-microvolt = <0xc96a8 0xc96a8 0x1312d0>;
			clock-latency-ns = <0x9c40>;
		};

		opp01 {
			opp-hz = <0x00 0x23c34600>;
			opp-microvolt = <0xc96a8 0xc96a8 0x1312d0>;
		};

		opp02 {
			opp-hz = <0x00 0x30a32c00>;
			opp-microvolt = <0xc96a8 0xc96a8 0x1312d0>;
		};

		opp03 {
			opp-hz = <0x00 0x3c14dc00>;
			opp-microvolt = <0xd59f8 0xd59f8 0x1312d0>;
		};

		opp04 {
			opp-hz = <0x00 0x47868c00>;
			opp-microvolt = <0xe7ef0 0xe7ef0 0x1312d0>;
		};

		opp05 {
			opp-hz = <0x00 0x54667200>;
			opp-microvolt = <0xfa3e8 0xfa3e8 0x1312d0>;
		};

		opp06 {
			opp-hz = <0x00 0x5fd82200>;
			opp-microvolt = <0x10c8e0 0x10c8e0 0x1312d0>;
		};

		opp07 {
			opp-hz = <0x00 0x6b49d200>;
			opp-microvolt = <0x124f80 0x124f80 0x1312d0>;
		};
	};

	opp-table-2 {
		compatible = "operating-points-v2";
		phandle = <0xcb>;

		opp00 {
			opp-hz = <0x00 0xbebc200>;
			opp-microvolt = <0xc96a8 0xc96a8 0x118c30>;
		};

		opp01 {
			opp-hz = <0x00 0x11b3dc40>;
			opp-microvolt = <0xc96a8 0xc96a8 0x118c30>;
		};

		opp02 {
			opp-hz = <0x00 0x17d78400>;
			opp-microvolt = <0xc96a8 0xc96a8 0x118c30>;
		};

		opp03 {
			opp-hz = <0x00 0x1dcd6500>;
			opp-microvolt = <0xd59f8 0xd59f8 0x118c30>;
		};

		opp04 {
			opp-hz = <0x00 0x23c34600>;
			opp-microvolt = <0xe1d48 0xe1d48 0x118c30>;
		};

		opp05 {
			opp-hz = <0x00 0x2faf0800>;
			opp-microvolt = <0x10c8e0 0x10c8e0 0x118c30>;
		};
	};

	chosen {
		stdout-path = "serial2:1500000n8";
	};

	backlight {
		compatible = "pwm-backlight";
		brightness-levels = <0x00 0x04 0x08 0x10 0x20 0x40 0x80 0xff>;
		default-brightness-level = <0x05>;
		pwms = <0xd2 0x00 0xf4240 0x00>;
		status = "disabled";
		phandle = <0xc3>;
	};

	external-gmac-clock {
		compatible = "fixed-clock";
		clock-frequency = <0x7735940>;
		clock-output-names = "clkin_gmac";
		#clock-cells = <0x00>;
		phandle = <0x21>;
	};

	gpio-keys {
		compatible = "gpio-keys";
		autorepeat;
		pinctrl-names = "default";
		pinctrl-0 = <0xd3>;

		key-power {
			debounce-interval = <0x64>;
			gpios = <0x29 0x05 0x01>;
			label = "GPIO Key Power";
			linux,code = <0x74>;
			wakeup-source;
		};
	};

	ir-receiver {
		compatible = "gpio-ir-receiver";
		gpios = <0x29 0x06 0x01>;
		pinctrl-0 = <0xd4>;
		pinctrl-names = "default";
	};

	leds {
		compatible = "gpio-leds";
		pinctrl-names = "default";
		pinctrl-0 = <0xd5 0xd6>;

		led-0 {
			label = "work";
			default-state = "on";
			gpios = <0x29 0x0b 0x00>;
		};

		led-1 {
			label = "diy";
			default-state = "off";
			gpios = <0x29 0x02 0x00>;
		};
	};

	pwm-fan {
		compatible = "pwm-fan";
		cooling-levels = <0x00 0x64 0x96 0xc8 0xff>;
		#cooling-cells = <0x02>;
		fan-supply = <0x1c>;
		pwms = <0xd7 0x00 0xc350 0x00>;
		phandle = <0x6a>;
	};

	sdio-pwrseq {
		compatible = "mmc-pwrseq-simple";
		clocks = <0x47 0x01>;
		clock-names = "ext_clock";
		pinctrl-names = "default";
		pinctrl-0 = <0xd8>;
		reset-gpios = <0x29 0x0a 0x01>;
		phandle = <0x25>;
	};

	sound {
		compatible = "audio-graph-card";
		label = "Analog";
		dais = <0xd9>;
	};

	sound-dit {
		compatible = "audio-graph-card";
		label = "SPDIF";
		dais = <0xda>;
	};

	spdif-dit {
		compatible = "linux,spdif-dit";
		#sound-dai-cells = <0x00>;

		port {

			endpoint {
				remote-endpoint = <0xdb>;
				phandle = <0xa4>;
			};
		};
	};

	avdd-regulator {
		compatible = "regulator-fixed";
		regulator-name = "avdd";
		regulator-min-microvolt = <0xa7d8c0>;
		regulator-max-microvolt = <0xa7d8c0>;
		vin-supply = <0xc4>;
		phandle = <0xc2>;
	};

	vcc12v-dcin {
		compatible = "regulator-fixed";
		regulator-name = "vcc12v_dcin";
		regulator-always-on;
		regulator-boot-on;
		regulator-min-microvolt = <0xb71b00>;
		regulator-max-microvolt = <0xb71b00>;
		phandle = <0x1c>;
	};

	vcc1v8-s3 {
		compatible = "regulator-fixed";
		regulator-name = "vcc1v8_s3";
		regulator-always-on;
		regulator-boot-on;
		regulator-min-microvolt = <0x1b7740>;
		regulator-max-microvolt = <0x1b7740>;
		vin-supply = <0x4c>;
		phandle = <0x3c>;
	};

	vcc3v0-sd {
		compatible = "regulator-fixed";
		enable-active-high;
		gpio = <0x29 0x01 0x00>;
		pinctrl-names = "default";
		pinctrl-0 = <0xdc>;
		regulator-name = "vcc3v0_sd";
		regulator-always-on;
		regulator-min-microvolt = <0x2dc6c0>;
		regulator-max-microvolt = <0x2dc6c0>;
		vin-supply = <0x4b>;
		phandle = <0x2d>;

		regulator-state-mem {
			regulator-off-in-suspend;
		};
	};

	vcc3v3-pcie-regulator {
		compatible = "regulator-fixed";
		enable-active-high;
		gpio = <0x93 0x18 0x00>;
		pinctrl-names = "default";
		pinctrl-0 = <0xdd>;
		regulator-name = "vcc3v3_pcie";
		regulator-always-on;
		regulator-boot-on;
		vin-supply = <0x1c>;
		phandle = <0x1d>;
	};

	vcc3v3-sys {
		compatible = "regulator-fixed";
		regulator-name = "vcc3v3_sys";
		regulator-always-on;
		regulator-boot-on;
		regulator-min-microvolt = <0x325aa0>;
		regulator-max-microvolt = <0x325aa0>;
		vin-supply = <0x8e>;
		phandle = <0x4b>;
	};

	vcc5v0-host-regulator {
		compatible = "regulator-fixed";
		enable-active-high;
		gpio = <0x96 0x1a 0x00>;
		pinctrl-names = "default";
		pinctrl-0 = <0xde>;
		regulator-name = "vcc5v0_host";
		regulator-always-on;
		vin-supply = <0xdf>;
		phandle = <0xa1>;
	};

	vcc5v0-typec-regulator {
		compatible = "regulator-fixed";
		enable-active-high;
		gpio = <0x93 0x03 0x00>;
		pinctrl-names = "default";
		pinctrl-0 = <0xe0>;
		regulator-name = "vcc5v0_typec";
		regulator-always-on;
		vin-supply = <0xdf>;
		phandle = <0x95>;
	};

	vcc5v0-sys {
		compatible = "regulator-fixed";
		regulator-name = "vcc5v0_sys";
		regulator-always-on;
		regulator-boot-on;
		regulator-min-microvolt = <0x4c4b40>;
		regulator-max-microvolt = <0x4c4b40>;
		vin-supply = <0x1c>;
		phandle = <0x8e>;
	};

	vcc5v0-usb {
		compatible = "regulator-fixed";
		regulator-name = "vcc5v0_usb";
		regulator-always-on;
		regulator-boot-on;
		regulator-min-microvolt = <0x4c4b40>;
		regulator-max-microvolt = <0x4c4b40>;
		vin-supply = <0x1c>;
		phandle = <0xdf>;
	};

	vdd-log {
		compatible = "pwm-regulator";
		pwms = <0xe1 0x00 0x61a8 0x01>;
		pwm-supply = <0x8e>;
		regulator-name = "vdd_log";
		regulator-always-on;
		regulator-boot-on;
		regulator-min-microvolt = "", "\f5";
		regulator-max-microvolt = <0x19f0a0>;
	};
};
